VERSION ""

NS_ :

BS_:

BU_: Gateway ESR
VAL_TABLE_ ForwardReverse 1 "Reverse" 0 "Forward" ;
VAL_TABLE_ LeftRight 1 "Right Clockwise" 0 "Left CounterClockwise" ;
VAL_TABLE_ ValidInvalid 1 "Valid" 0 "Invalid" ;
VAL_TABLE_ TrueFalse 1 "True" 0 "False" ;

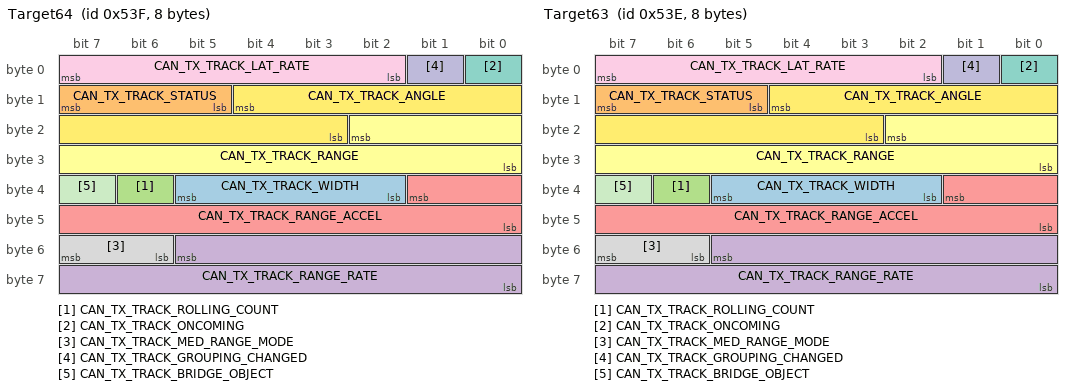
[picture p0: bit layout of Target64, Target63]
BO_ 1343 Target64: 8 Vector__XXX
 SG_ CAN_TX_TRACK_WIDTH : 37|4@0+ (0.5,0) [0|7.5] "" Vector__XXX
 SG_ CAN_TX_TRACK_STATUS : 15|3@0+ (1,0) [0|7] "" Vector__XXX
 SG_ CAN_TX_TRACK_ROLLING_COUNT : 38|1@0+ (1,0) [0|1] "" Vector__XXX
 SG_ CAN_TX_TRACK_RANGE_RATE : 53|14@0- (0.01,0) [-81.92|81.91] "m/s" Vector__XXX
 SG_ CAN_TX_TRACK_RANGE_ACCEL : 33|10@0- (0.05,0) [-25.6|25.55] "m/s^2" Vector__XXX
 SG_ CAN_TX_TRACK_RANGE : 18|11@0+ (0.1,0) [0|204.7] "m" Vector__XXX
 SG_ CAN_TX_TRACK_ONCOMING : 0|1@0+ (1,0) [0|1] "" Vector__XXX
 SG_ CAN_TX_TRACK_MED_RANGE_MODE : 55|2@0+ (1,0) [0|3] "" Vector__XXX
 SG_ CAN_TX_TRACK_LAT_RATE : 7|6@0- (0.25,0) [-8|7.75] "" Vector__XXX
 SG_ CAN_TX_TRACK_GROUPING_CHANGED : 1|1@0+ (1,0) [0|1] "" Vector__XXX
 SG_ CAN_TX_TRACK_BRIDGE_OBJECT : 39|1@0+ (1,0) [0|1] "" Vector__XXX
 SG_ CAN_TX_TRACK_ANGLE : 12|10@0- (0.1,0) [-51.2|51.1] "" Vector__XXX

BO_ 1342 Target63: 8 Vector__XXX
 SG_ CAN_TX_TRACK_WIDTH : 37|4@0+ (0.5,0) [0|7.5] "" Vector__XXX
 SG_ CAN_TX_TRACK_STATUS : 15|3@0+ (1,0) [0|7] "" Vector__XXX
 SG_ CAN_TX_TRACK_ROLLING_COUNT : 38|1@0+ (1,0) [0|1] "" Vector__XXX
 SG_ CAN_TX_TRACK_RANGE_RATE : 53|14@0- (0.01,0) [-81.92|81.91] "m/s" Vector__XXX
 SG_ CAN_TX_TRACK_RANGE_ACCEL : 33|10@0- (0.05,0) [-25.6|25.55] "m/s^2" Vector__XXX
 SG_ CAN_TX_TRACK_RANGE : 18|11@0+ (0.1,0) [0|204.7] "m" Vector__XXX
 SG_ CAN_TX_TRACK_ONCOMING : 0|1@0+ (1,0) [0|1] "" Vector__XXX
 SG_ CAN_TX_TRACK_MED_RANGE_MODE : 55|2@0+ (1,0) [0|3] "" Vector__XXX
 SG_ CAN_TX_TRACK_LAT_RATE : 7|6@0- (0.25,0) [-8|7.75] "" Vector__XXX
 SG_ CAN_TX_TRACK_GROUPING_CHANGED : 1|1@0+ (1,0) [0|1] "" Vector__XXX
 SG_ CAN_TX_TRACK_BRIDGE_OBJECT : 39|1@0+ (1,0) [0|1] "" Vector__XXX
 SG_ CAN_TX_TRACK_ANGLE : 12|10@0- (0.1,0) [-51.2|51.1] "" Vector__XXX

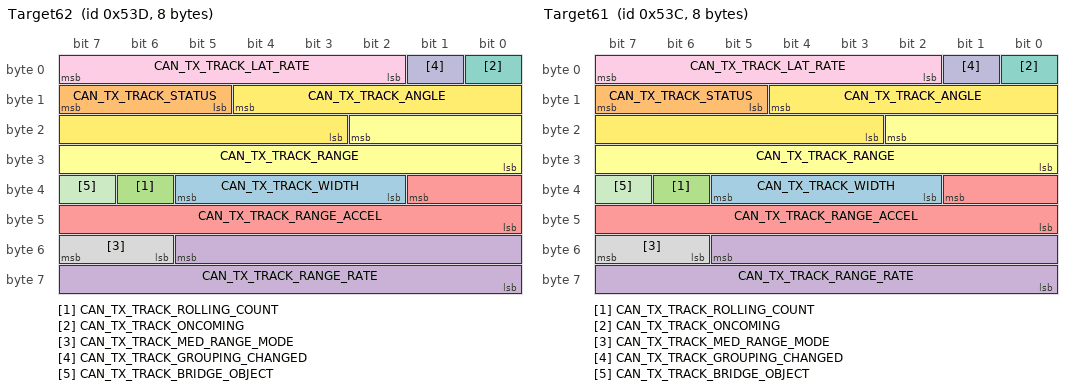
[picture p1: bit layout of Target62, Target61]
BO_ 1341 Target62: 8 Vector__XXX
 SG_ CAN_TX_TRACK_WIDTH : 37|4@0+ (0.5,0) [0|7.5] "" Vector__XXX
 SG_ CAN_TX_TRACK_STATUS : 15|3@0+ (1,0) [0|7] "" Vector__XXX
 SG_ CAN_TX_TRACK_ROLLING_COUNT : 38|1@0+ (1,0) [0|1] "" Vector__XXX
 SG_ CAN_TX_TRACK_RANGE_RATE : 53|14@0- (0.01,0) [-81.92|81.91] "m/s" Vector__XXX
 SG_ CAN_TX_TRACK_RANGE_ACCEL : 33|10@0- (0.05,0) [-25.6|25.55] "m/s^2" Vector__XXX
 SG_ CAN_TX_TRACK_RANGE : 18|11@0+ (0.1,0) [0|204.7] "m" Vector__XXX
 SG_ CAN_TX_TRACK_ONCOMING : 0|1@0+ (1,0) [0|1] "" Vector__XXX
 SG_ CAN_TX_TRACK_MED_RANGE_MODE : 55|2@0+ (1,0) [0|3] "" Vector__XXX
 SG_ CAN_TX_TRACK_LAT_RATE : 7|6@0- (0.25,0) [-8|7.75] "" Vector__XXX
 SG_ CAN_TX_TRACK_GROUPING_CHANGED : 1|1@0+ (1,0) [0|1] "" Vector__XXX
 SG_ CAN_TX_TRACK_BRIDGE_OBJECT : 39|1@0+ (1,0) [0|1] "" Vector__XXX
 SG_ CAN_TX_TRACK_ANGLE : 12|10@0- (0.1,0) [-51.2|51.1] "" Vector__XXX

BO_ 1340 Target61: 8 Vector__XXX
 SG_ CAN_TX_TRACK_WIDTH : 37|4@0+ (0.5,0) [0|7.5] "" Vector__XXX
 SG_ CAN_TX_TRACK_STATUS : 15|3@0+ (1,0) [0|7] "" Vector__XXX
 SG_ CAN_TX_TRACK_ROLLING_COUNT : 38|1@0+ (1,0) [0|1] "" Vector__XXX
 SG_ CAN_TX_TRACK_RANGE_RATE : 53|14@0- (0.01,0) [-81.92|81.91] "m/s" Vector__XXX
 SG_ CAN_TX_TRACK_RANGE_ACCEL : 33|10@0- (0.05,0) [-25.6|25.55] "m/s^2" Vector__XXX
 SG_ CAN_TX_TRACK_RANGE : 18|11@0+ (0.1,0) [0|204.7] "m" Vector__XXX
 SG_ CAN_TX_TRACK_ONCOMING : 0|1@0+ (1,0) [0|1] "" Vector__XXX
 SG_ CAN_TX_TRACK_MED_RANGE_MODE : 55|2@0+ (1,0) [0|3] "" Vector__XXX
 SG_ CAN_TX_TRACK_LAT_RATE : 7|6@0- (0.25,0) [-8|7.75] "" Vector__XXX
 SG_ CAN_TX_TRACK_GROUPING_CHANGED : 1|1@0+ (1,0) [0|1] "" Vector__XXX
 SG_ CAN_TX_TRACK_BRIDGE_OBJECT : 39|1@0+ (1,0) [0|1] "" Vector__XXX
 SG_ CAN_TX_TRACK_ANGLE : 12|10@0- (0.1,0) [-51.2|51.1] "" Vector__XXX

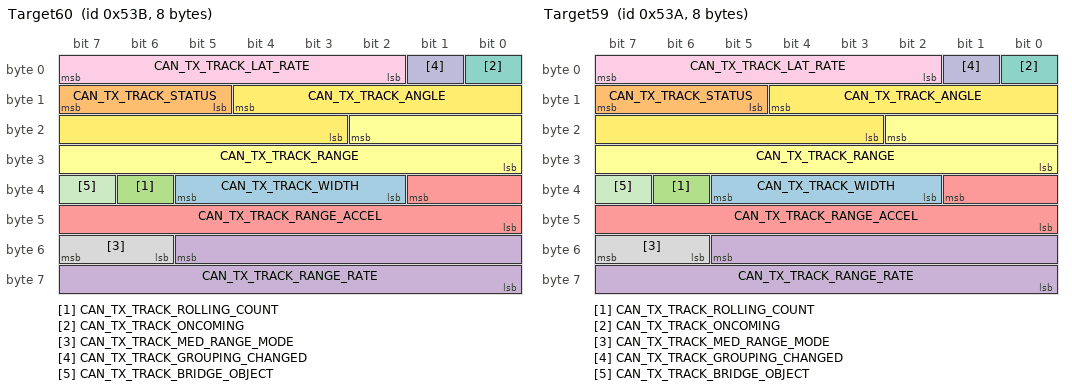
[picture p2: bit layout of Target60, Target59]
BO_ 1339 Target60: 8 Vector__XXX
 SG_ CAN_TX_TRACK_WIDTH : 37|4@0+ (0.5,0) [0|7.5] "" Vector__XXX
 SG_ CAN_TX_TRACK_STATUS : 15|3@0+ (1,0) [0|7] "" Vector__XXX
 SG_ CAN_TX_TRACK_ROLLING_COUNT : 38|1@0+ (1,0) [0|1] "" Vector__XXX
 SG_ CAN_TX_TRACK_RANGE_RATE : 53|14@0- (0.01,0) [-81.92|81.91] "m/s" Vector__XXX
 SG_ CAN_TX_TRACK_RANGE_ACCEL : 33|10@0- (0.05,0) [-25.6|25.55] "m/s^2" Vector__XXX
 SG_ CAN_TX_TRACK_RANGE : 18|11@0+ (0.1,0) [0|204.7] "m" Vector__XXX
 SG_ CAN_TX_TRACK_ONCOMING : 0|1@0+ (1,0) [0|1] "" Vector__XXX
 SG_ CAN_TX_TRACK_MED_RANGE_MODE : 55|2@0+ (1,0) [0|3] "" Vector__XXX
 SG_ CAN_TX_TRACK_LAT_RATE : 7|6@0- (0.25,0) [-8|7.75] "" Vector__XXX
 SG_ CAN_TX_TRACK_GROUPING_CHANGED : 1|1@0+ (1,0) [0|1] "" Vector__XXX
 SG_ CAN_TX_TRACK_BRIDGE_OBJECT : 39|1@0+ (1,0) [0|1] "" Vector__XXX
 SG_ CAN_TX_TRACK_ANGLE : 12|10@0- (0.1,0) [-51.2|51.1] "" Vector__XXX

BO_ 1338 Target59: 8 Vector__XXX
 SG_ CAN_TX_TRACK_WIDTH : 37|4@0+ (0.5,0) [0|7.5] "" Vector__XXX
 SG_ CAN_TX_TRACK_STATUS : 15|3@0+ (1,0) [0|7] "" Vector__XXX
 SG_ CAN_TX_TRACK_ROLLING_COUNT : 38|1@0+ (1,0) [0|1] "" Vector__XXX
 SG_ CAN_TX_TRACK_RANGE_RATE : 53|14@0- (0.01,0) [-81.92|81.91] "m/s" Vector__XXX
 SG_ CAN_TX_TRACK_RANGE_ACCEL : 33|10@0- (0.05,0) [-25.6|25.55] "m/s^2" Vector__XXX
 SG_ CAN_TX_TRACK_RANGE : 18|11@0+ (0.1,0) [0|204.7] "m" Vector__XXX
 SG_ CAN_TX_TRACK_ONCOMING : 0|1@0+ (1,0) [0|1] "" Vector__XXX
 SG_ CAN_TX_TRACK_MED_RANGE_MODE : 55|2@0+ (1,0) [0|3] "" Vector__XXX
 SG_ CAN_TX_TRACK_LAT_RATE : 7|6@0- (0.25,0) [-8|7.75] "" Vector__XXX
 SG_ CAN_TX_TRACK_GROUPING_CHANGED : 1|1@0+ (1,0) [0|1] "" Vector__XXX
 SG_ CAN_TX_TRACK_BRIDGE_OBJECT : 39|1@0+ (1,0) [0|1] "" Vector__XXX
 SG_ CAN_TX_TRACK_ANGLE : 12|10@0- (0.1,0) [-51.2|51.1] "" Vector__XXX

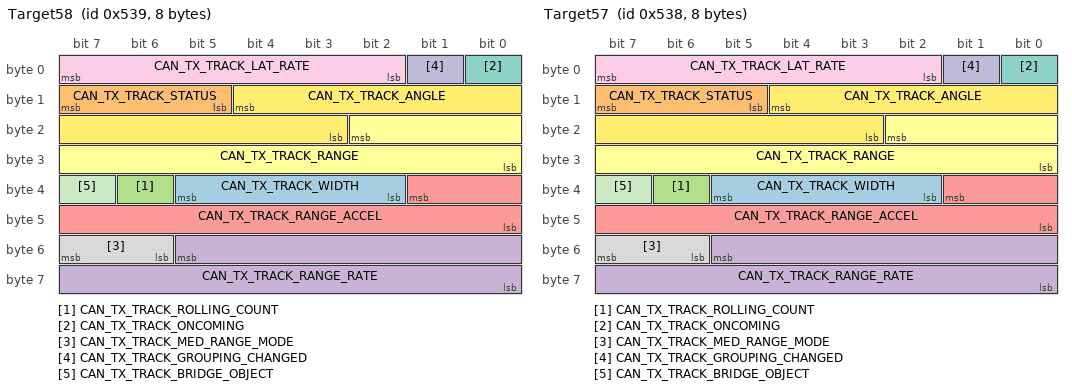
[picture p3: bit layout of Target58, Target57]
BO_ 1337 Target58: 8 Vector__XXX
 SG_ CAN_TX_TRACK_WIDTH : 37|4@0+ (0.5,0) [0|7.5] "" Vector__XXX
 SG_ CAN_TX_TRACK_STATUS : 15|3@0+ (1,0) [0|7] "" Vector__XXX
 SG_ CAN_TX_TRACK_ROLLING_COUNT : 38|1@0+ (1,0) [0|1] "" Vector__XXX
 SG_ CAN_TX_TRACK_RANGE_RATE : 53|14@0- (0.01,0) [-81.92|81.91] "m/s" Vector__XXX
 SG_ CAN_TX_TRACK_RANGE_ACCEL : 33|10@0- (0.05,0) [-25.6|25.55] "m/s^2" Vector__XXX
 SG_ CAN_TX_TRACK_RANGE : 18|11@0+ (0.1,0) [0|204.7] "m" Vector__XXX
 SG_ CAN_TX_TRACK_ONCOMING : 0|1@0+ (1,0) [0|1] "" Vector__XXX
 SG_ CAN_TX_TRACK_MED_RANGE_MODE : 55|2@0+ (1,0) [0|3] "" Vector__XXX
 SG_ CAN_TX_TRACK_LAT_RATE : 7|6@0- (0.25,0) [-8|7.75] "" Vector__XXX
 SG_ CAN_TX_TRACK_GROUPING_CHANGED : 1|1@0+ (1,0) [0|1] "" Vector__XXX
 SG_ CAN_TX_TRACK_BRIDGE_OBJECT : 39|1@0+ (1,0) [0|1] "" Vector__XXX
 SG_ CAN_TX_TRACK_ANGLE : 12|10@0- (0.1,0) [-51.2|51.1] "" Vector__XXX

BO_ 1336 Target57: 8 Vector__XXX
 SG_ CAN_TX_TRACK_WIDTH : 37|4@0+ (0.5,0) [0|7.5] "" Vector__XXX
 SG_ CAN_TX_TRACK_STATUS : 15|3@0+ (1,0) [0|7] "" Vector__XXX
 SG_ CAN_TX_TRACK_ROLLING_COUNT : 38|1@0+ (1,0) [0|1] "" Vector__XXX
 SG_ CAN_TX_TRACK_RANGE_RATE : 53|14@0- (0.01,0) [-81.92|81.91] "m/s" Vector__XXX
 SG_ CAN_TX_TRACK_RANGE_ACCEL : 33|10@0- (0.05,0) [-25.6|25.55] "m/s^2" Vector__XXX
 SG_ CAN_TX_TRACK_RANGE : 18|11@0+ (0.1,0) [0|204.7] "m" Vector__XXX
 SG_ CAN_TX_TRACK_ONCOMING : 0|1@0+ (1,0) [0|1] "" Vector__XXX
 SG_ CAN_TX_TRACK_MED_RANGE_MODE : 55|2@0+ (1,0) [0|3] "" Vector__XXX
 SG_ CAN_TX_TRACK_LAT_RATE : 7|6@0- (0.25,0) [-8|7.75] "" Vector__XXX
 SG_ CAN_TX_TRACK_GROUPING_CHANGED : 1|1@0+ (1,0) [0|1] "" Vector__XXX
 SG_ CAN_TX_TRACK_BRIDGE_OBJECT : 39|1@0+ (1,0) [0|1] "" Vector__XXX
 SG_ CAN_TX_TRACK_ANGLE : 12|10@0- (0.1,0) [-51.2|51.1] "" Vector__XXX

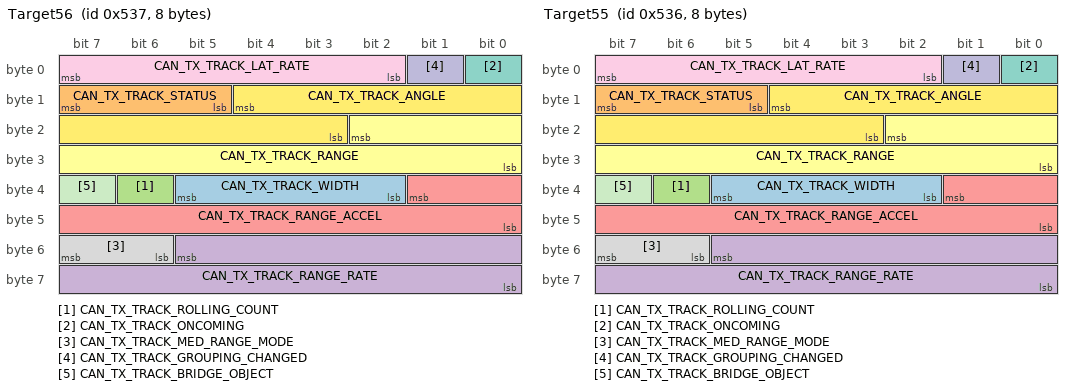
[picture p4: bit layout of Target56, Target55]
BO_ 1335 Target56: 8 Vector__XXX
 SG_ CAN_TX_TRACK_WIDTH : 37|4@0+ (0.5,0) [0|7.5] "" Vector__XXX
 SG_ CAN_TX_TRACK_STATUS : 15|3@0+ (1,0) [0|7] "" Vector__XXX
 SG_ CAN_TX_TRACK_ROLLING_COUNT : 38|1@0+ (1,0) [0|1] "" Vector__XXX
 SG_ CAN_TX_TRACK_RANGE_RATE : 53|14@0- (0.01,0) [-81.92|81.91] "m/s" Vector__XXX
 SG_ CAN_TX_TRACK_RANGE_ACCEL : 33|10@0- (0.05,0) [-25.6|25.55] "m/s^2" Vector__XXX
 SG_ CAN_TX_TRACK_RANGE : 18|11@0+ (0.1,0) [0|204.7] "m" Vector__XXX
 SG_ CAN_TX_TRACK_ONCOMING : 0|1@0+ (1,0) [0|1] "" Vector__XXX
 SG_ CAN_TX_TRACK_MED_RANGE_MODE : 55|2@0+ (1,0) [0|3] "" Vector__XXX
 SG_ CAN_TX_TRACK_LAT_RATE : 7|6@0- (0.25,0) [-8|7.75] "" Vector__XXX
 SG_ CAN_TX_TRACK_GROUPING_CHANGED : 1|1@0+ (1,0) [0|1] "" Vector__XXX
 SG_ CAN_TX_TRACK_BRIDGE_OBJECT : 39|1@0+ (1,0) [0|1] "" Vector__XXX
 SG_ CAN_TX_TRACK_ANGLE : 12|10@0- (0.1,0) [-51.2|51.1] "" Vector__XXX

BO_ 1334 Target55: 8 Vector__XXX
 SG_ CAN_TX_TRACK_WIDTH : 37|4@0+ (0.5,0) [0|7.5] "" Vector__XXX
 SG_ CAN_TX_TRACK_STATUS : 15|3@0+ (1,0) [0|7] "" Vector__XXX
 SG_ CAN_TX_TRACK_ROLLING_COUNT : 38|1@0+ (1,0) [0|1] "" Vector__XXX
 SG_ CAN_TX_TRACK_RANGE_RATE : 53|14@0- (0.01,0) [-81.92|81.91] "m/s" Vector__XXX
 SG_ CAN_TX_TRACK_RANGE_ACCEL : 33|10@0- (0.05,0) [-25.6|25.55] "m/s^2" Vector__XXX
 SG_ CAN_TX_TRACK_RANGE : 18|11@0+ (0.1,0) [0|204.7] "m" Vector__XXX
 SG_ CAN_TX_TRACK_ONCOMING : 0|1@0+ (1,0) [0|1] "" Vector__XXX
 SG_ CAN_TX_TRACK_MED_RANGE_MODE : 55|2@0+ (1,0) [0|3] "" Vector__XXX
 SG_ CAN_TX_TRACK_LAT_RATE : 7|6@0- (0.25,0) [-8|7.75] "" Vector__XXX
 SG_ CAN_TX_TRACK_GROUPING_CHANGED : 1|1@0+ (1,0) [0|1] "" Vector__XXX
 SG_ CAN_TX_TRACK_BRIDGE_OBJECT : 39|1@0+ (1,0) [0|1] "" Vector__XXX
 SG_ CAN_TX_TRACK_ANGLE : 12|10@0- (0.1,0) [-51.2|51.1] "" Vector__XXX

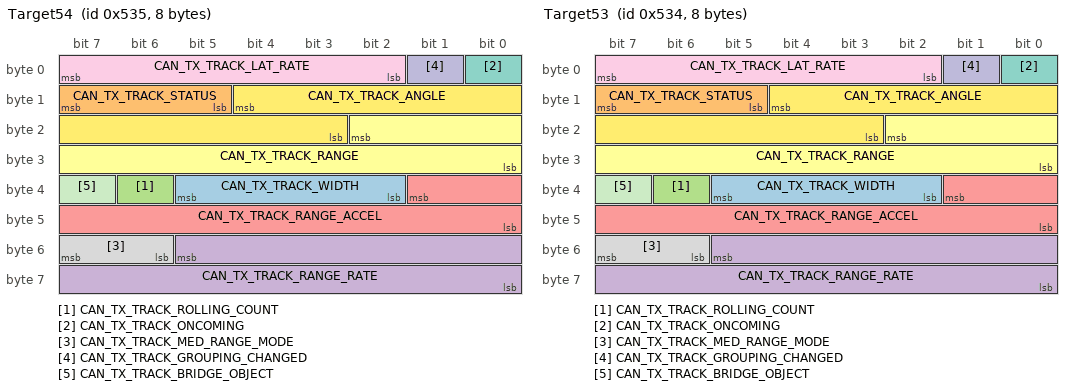
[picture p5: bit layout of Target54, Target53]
BO_ 1333 Target54: 8 Vector__XXX
 SG_ CAN_TX_TRACK_WIDTH : 37|4@0+ (0.5,0) [0|7.5] "" Vector__XXX
 SG_ CAN_TX_TRACK_STATUS : 15|3@0+ (1,0) [0|7] "" Vector__XXX
 SG_ CAN_TX_TRACK_ROLLING_COUNT : 38|1@0+ (1,0) [0|1] "" Vector__XXX
 SG_ CAN_TX_TRACK_RANGE_RATE : 53|14@0- (0.01,0) [-81.92|81.91] "m/s" Vector__XXX
 SG_ CAN_TX_TRACK_RANGE_ACCEL : 33|10@0- (0.05,0) [-25.6|25.55] "m/s^2" Vector__XXX
 SG_ CAN_TX_TRACK_RANGE : 18|11@0+ (0.1,0) [0|204.7] "m" Vector__XXX
 SG_ CAN_TX_TRACK_ONCOMING : 0|1@0+ (1,0) [0|1] "" Vector__XXX
 SG_ CAN_TX_TRACK_MED_RANGE_MODE : 55|2@0+ (1,0) [0|3] "" Vector__XXX
 SG_ CAN_TX_TRACK_LAT_RATE : 7|6@0- (0.25,0) [-8|7.75] "" Vector__XXX
 SG_ CAN_TX_TRACK_GROUPING_CHANGED : 1|1@0+ (1,0) [0|1] "" Vector__XXX
 SG_ CAN_TX_TRACK_BRIDGE_OBJECT : 39|1@0+ (1,0) [0|1] "" Vector__XXX
 SG_ CAN_TX_TRACK_ANGLE : 12|10@0- (0.1,0) [-51.2|51.1] "" Vector__XXX

BO_ 1332 Target53: 8 Vector__XXX
 SG_ CAN_TX_TRACK_WIDTH : 37|4@0+ (0.5,0) [0|7.5] "" Vector__XXX
 SG_ CAN_TX_TRACK_STATUS : 15|3@0+ (1,0) [0|7] "" Vector__XXX
 SG_ CAN_TX_TRACK_ROLLING_COUNT : 38|1@0+ (1,0) [0|1] "" Vector__XXX
 SG_ CAN_TX_TRACK_RANGE_RATE : 53|14@0- (0.01,0) [-81.92|81.91] "m/s" Vector__XXX
 SG_ CAN_TX_TRACK_RANGE_ACCEL : 33|10@0- (0.05,0) [-25.6|25.55] "m/s^2" Vector__XXX
 SG_ CAN_TX_TRACK_RANGE : 18|11@0+ (0.1,0) [0|204.7] "m" Vector__XXX
 SG_ CAN_TX_TRACK_ONCOMING : 0|1@0+ (1,0) [0|1] "" Vector__XXX
 SG_ CAN_TX_TRACK_MED_RANGE_MODE : 55|2@0+ (1,0) [0|3] "" Vector__XXX
 SG_ CAN_TX_TRACK_LAT_RATE : 7|6@0- (0.25,0) [-8|7.75] "" Vector__XXX
 SG_ CAN_TX_TRACK_GROUPING_CHANGED : 1|1@0+ (1,0) [0|1] "" Vector__XXX
 SG_ CAN_TX_TRACK_BRIDGE_OBJECT : 39|1@0+ (1,0) [0|1] "" Vector__XXX
 SG_ CAN_TX_TRACK_ANGLE : 12|10@0- (0.1,0) [-51.2|51.1] "" Vector__XXX

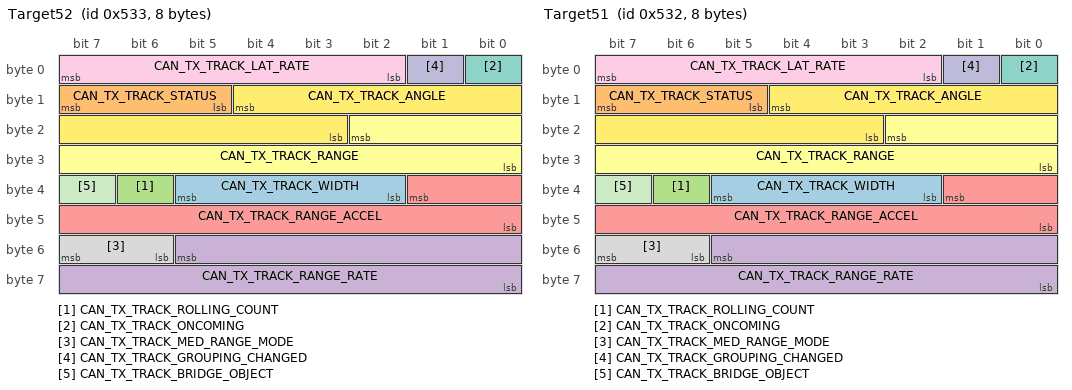
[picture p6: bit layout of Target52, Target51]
BO_ 1331 Target52: 8 Vector__XXX
 SG_ CAN_TX_TRACK_WIDTH : 37|4@0+ (0.5,0) [0|7.5] "" Vector__XXX
 SG_ CAN_TX_TRACK_STATUS : 15|3@0+ (1,0) [0|7] "" Vector__XXX
 SG_ CAN_TX_TRACK_ROLLING_COUNT : 38|1@0+ (1,0) [0|1] "" Vector__XXX
 SG_ CAN_TX_TRACK_RANGE_RATE : 53|14@0- (0.01,0) [-81.92|81.91] "m/s" Vector__XXX
 SG_ CAN_TX_TRACK_RANGE_ACCEL : 33|10@0- (0.05,0) [-25.6|25.55] "m/s^2" Vector__XXX
 SG_ CAN_TX_TRACK_RANGE : 18|11@0+ (0.1,0) [0|204.7] "m" Vector__XXX
 SG_ CAN_TX_TRACK_ONCOMING : 0|1@0+ (1,0) [0|1] "" Vector__XXX
 SG_ CAN_TX_TRACK_MED_RANGE_MODE : 55|2@0+ (1,0) [0|3] "" Vector__XXX
 SG_ CAN_TX_TRACK_LAT_RATE : 7|6@0- (0.25,0) [-8|7.75] "" Vector__XXX
 SG_ CAN_TX_TRACK_GROUPING_CHANGED : 1|1@0+ (1,0) [0|1] "" Vector__XXX
 SG_ CAN_TX_TRACK_BRIDGE_OBJECT : 39|1@0+ (1,0) [0|1] "" Vector__XXX
 SG_ CAN_TX_TRACK_ANGLE : 12|10@0- (0.1,0) [-51.2|51.1] "" Vector__XXX

BO_ 1330 Target51: 8 Vector__XXX
 SG_ CAN_TX_TRACK_WIDTH : 37|4@0+ (0.5,0) [0|7.5] "" Vector__XXX
 SG_ CAN_TX_TRACK_STATUS : 15|3@0+ (1,0) [0|7] "" Vector__XXX
 SG_ CAN_TX_TRACK_ROLLING_COUNT : 38|1@0+ (1,0) [0|1] "" Vector__XXX
 SG_ CAN_TX_TRACK_RANGE_RATE : 53|14@0- (0.01,0) [-81.92|81.91] "m/s" Vector__XXX
 SG_ CAN_TX_TRACK_RANGE_ACCEL : 33|10@0- (0.05,0) [-25.6|25.55] "m/s^2" Vector__XXX
 SG_ CAN_TX_TRACK_RANGE : 18|11@0+ (0.1,0) [0|204.7] "m" Vector__XXX
 SG_ CAN_TX_TRACK_ONCOMING : 0|1@0+ (1,0) [0|1] "" Vector__XXX
 SG_ CAN_TX_TRACK_MED_RANGE_MODE : 55|2@0+ (1,0) [0|3] "" Vector__XXX
 SG_ CAN_TX_TRACK_LAT_RATE : 7|6@0- (0.25,0) [-8|7.75] "" Vector__XXX
 SG_ CAN_TX_TRACK_GROUPING_CHANGED : 1|1@0+ (1,0) [0|1] "" Vector__XXX
 SG_ CAN_TX_TRACK_BRIDGE_OBJECT : 39|1@0+ (1,0) [0|1] "" Vector__XXX
 SG_ CAN_TX_TRACK_ANGLE : 12|10@0- (0.1,0) [-51.2|51.1] "" Vector__XXX

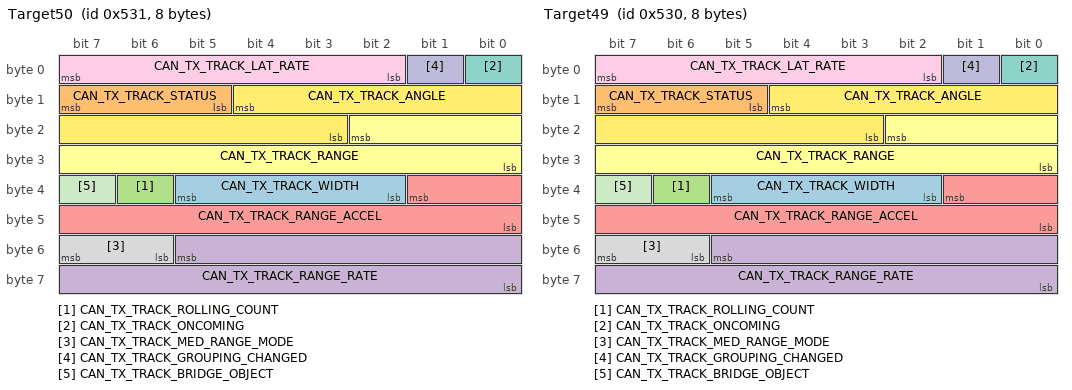
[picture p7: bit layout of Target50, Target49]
BO_ 1329 Target50: 8 Vector__XXX
 SG_ CAN_TX_TRACK_WIDTH : 37|4@0+ (0.5,0) [0|7.5] "" Vector__XXX
 SG_ CAN_TX_TRACK_STATUS : 15|3@0+ (1,0) [0|7] "" Vector__XXX
 SG_ CAN_TX_TRACK_ROLLING_COUNT : 38|1@0+ (1,0) [0|1] "" Vector__XXX
 SG_ CAN_TX_TRACK_RANGE_RATE : 53|14@0- (0.01,0) [-81.92|81.91] "m/s" Vector__XXX
 SG_ CAN_TX_TRACK_RANGE_ACCEL : 33|10@0- (0.05,0) [-25.6|25.55] "m/s^2" Vector__XXX
 SG_ CAN_TX_TRACK_RANGE : 18|11@0+ (0.1,0) [0|204.7] "m" Vector__XXX
 SG_ CAN_TX_TRACK_ONCOMING : 0|1@0+ (1,0) [0|1] "" Vector__XXX
 SG_ CAN_TX_TRACK_MED_RANGE_MODE : 55|2@0+ (1,0) [0|3] "" Vector__XXX
 SG_ CAN_TX_TRACK_LAT_RATE : 7|6@0- (0.25,0) [-8|7.75] "" Vector__XXX
 SG_ CAN_TX_TRACK_GROUPING_CHANGED : 1|1@0+ (1,0) [0|1] "" Vector__XXX
 SG_ CAN_TX_TRACK_BRIDGE_OBJECT : 39|1@0+ (1,0) [0|1] "" Vector__XXX
 SG_ CAN_TX_TRACK_ANGLE : 12|10@0- (0.1,0) [-51.2|51.1] "" Vector__XXX

BO_ 1328 Target49: 8 Vector__XXX
 SG_ CAN_TX_TRACK_WIDTH : 37|4@0+ (0.5,0) [0|7.5] "" Vector__XXX
 SG_ CAN_TX_TRACK_STATUS : 15|3@0+ (1,0) [0|7] "" Vector__XXX
 SG_ CAN_TX_TRACK_ROLLING_COUNT : 38|1@0+ (1,0) [0|1] "" Vector__XXX
 SG_ CAN_TX_TRACK_RANGE_RATE : 53|14@0- (0.01,0) [-81.92|81.91] "m/s" Vector__XXX
 SG_ CAN_TX_TRACK_RANGE_ACCEL : 33|10@0- (0.05,0) [-25.6|25.55] "m/s^2" Vector__XXX
 SG_ CAN_TX_TRACK_RANGE : 18|11@0+ (0.1,0) [0|204.7] "m" Vector__XXX
 SG_ CAN_TX_TRACK_ONCOMING : 0|1@0+ (1,0) [0|1] "" Vector__XXX
 SG_ CAN_TX_TRACK_MED_RANGE_MODE : 55|2@0+ (1,0) [0|3] "" Vector__XXX
 SG_ CAN_TX_TRACK_LAT_RATE : 7|6@0- (0.25,0) [-8|7.75] "" Vector__XXX
 SG_ CAN_TX_TRACK_GROUPING_CHANGED : 1|1@0+ (1,0) [0|1] "" Vector__XXX
 SG_ CAN_TX_TRACK_BRIDGE_OBJECT : 39|1@0+ (1,0) [0|1] "" Vector__XXX
 SG_ CAN_TX_TRACK_ANGLE : 12|10@0- (0.1,0) [-51.2|51.1] "" Vector__XXX

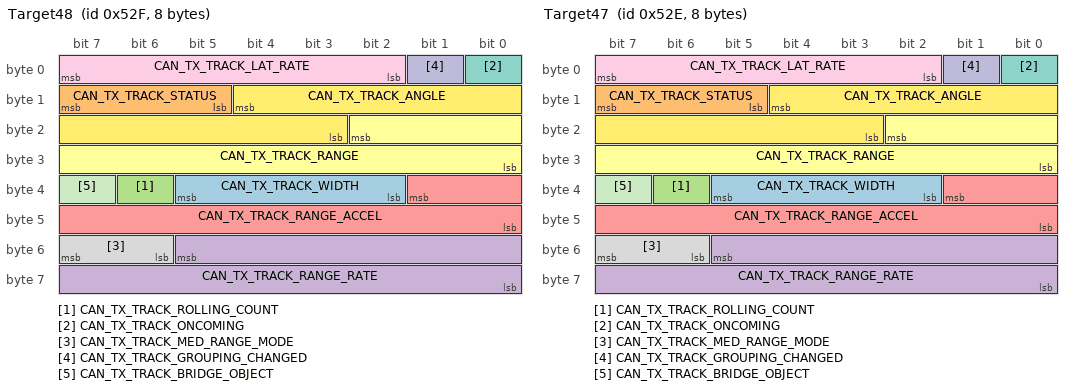
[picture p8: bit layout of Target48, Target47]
BO_ 1327 Target48: 8 Vector__XXX
 SG_ CAN_TX_TRACK_WIDTH : 37|4@0+ (0.5,0) [0|7.5] "" Vector__XXX
 SG_ CAN_TX_TRACK_STATUS : 15|3@0+ (1,0) [0|7] "" Vector__XXX
 SG_ CAN_TX_TRACK_ROLLING_COUNT : 38|1@0+ (1,0) [0|1] "" Vector__XXX
 SG_ CAN_TX_TRACK_RANGE_RATE : 53|14@0- (0.01,0) [-81.92|81.91] "m/s" Vector__XXX
 SG_ CAN_TX_TRACK_RANGE_ACCEL : 33|10@0- (0.05,0) [-25.6|25.55] "m/s^2" Vector__XXX
 SG_ CAN_TX_TRACK_RANGE : 18|11@0+ (0.1,0) [0|204.7] "m" Vector__XXX
 SG_ CAN_TX_TRACK_ONCOMING : 0|1@0+ (1,0) [0|1] "" Vector__XXX
 SG_ CAN_TX_TRACK_MED_RANGE_MODE : 55|2@0+ (1,0) [0|3] "" Vector__XXX
 SG_ CAN_TX_TRACK_LAT_RATE : 7|6@0- (0.25,0) [-8|7.75] "" Vector__XXX
 SG_ CAN_TX_TRACK_GROUPING_CHANGED : 1|1@0+ (1,0) [0|1] "" Vector__XXX
 SG_ CAN_TX_TRACK_BRIDGE_OBJECT : 39|1@0+ (1,0) [0|1] "" Vector__XXX
 SG_ CAN_TX_TRACK_ANGLE : 12|10@0- (0.1,0) [-51.2|51.1] "" Vector__XXX

BO_ 1326 Target47: 8 Vector__XXX
 SG_ CAN_TX_TRACK_WIDTH : 37|4@0+ (0.5,0) [0|7.5] "" Vector__XXX
 SG_ CAN_TX_TRACK_STATUS : 15|3@0+ (1,0) [0|7] "" Vector__XXX
 SG_ CAN_TX_TRACK_ROLLING_COUNT : 38|1@0+ (1,0) [0|1] "" Vector__XXX
 SG_ CAN_TX_TRACK_RANGE_RATE : 53|14@0- (0.01,0) [-81.92|81.91] "m/s" Vector__XXX
 SG_ CAN_TX_TRACK_RANGE_ACCEL : 33|10@0- (0.05,0) [-25.6|25.55] "m/s^2" Vector__XXX
 SG_ CAN_TX_TRACK_RANGE : 18|11@0+ (0.1,0) [0|204.7] "m" Vector__XXX
 SG_ CAN_TX_TRACK_ONCOMING : 0|1@0+ (1,0) [0|1] "" Vector__XXX
 SG_ CAN_TX_TRACK_MED_RANGE_MODE : 55|2@0+ (1,0) [0|3] "" Vector__XXX
 SG_ CAN_TX_TRACK_LAT_RATE : 7|6@0- (0.25,0) [-8|7.75] "" Vector__XXX
 SG_ CAN_TX_TRACK_GROUPING_CHANGED : 1|1@0+ (1,0) [0|1] "" Vector__XXX
 SG_ CAN_TX_TRACK_BRIDGE_OBJECT : 39|1@0+ (1,0) [0|1] "" Vector__XXX
 SG_ CAN_TX_TRACK_ANGLE : 12|10@0- (0.1,0) [-51.2|51.1] "" Vector__XXX

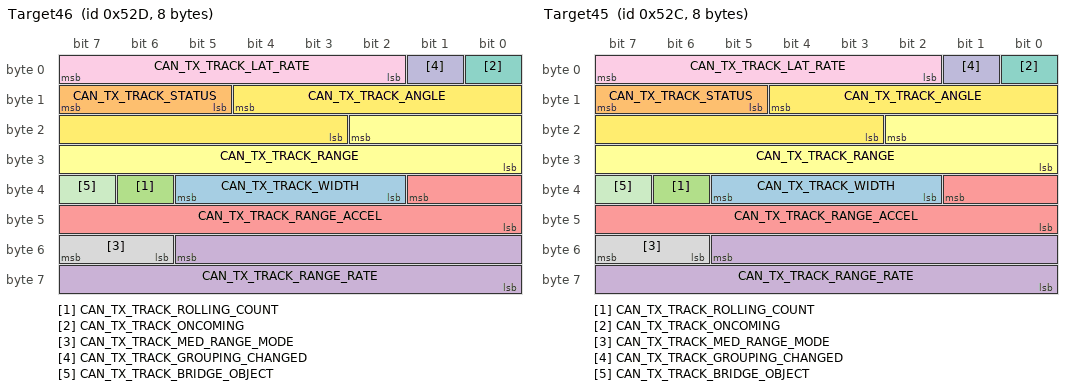
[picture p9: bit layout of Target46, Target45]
BO_ 1325 Target46: 8 Vector__XXX
 SG_ CAN_TX_TRACK_WIDTH : 37|4@0+ (0.5,0) [0|7.5] "" Vector__XXX
 SG_ CAN_TX_TRACK_STATUS : 15|3@0+ (1,0) [0|7] "" Vector__XXX
 SG_ CAN_TX_TRACK_ROLLING_COUNT : 38|1@0+ (1,0) [0|1] "" Vector__XXX
 SG_ CAN_TX_TRACK_RANGE_RATE : 53|14@0- (0.01,0) [-81.92|81.91] "m/s" Vector__XXX
 SG_ CAN_TX_TRACK_RANGE_ACCEL : 33|10@0- (0.05,0) [-25.6|25.55] "m/s^2" Vector__XXX
 SG_ CAN_TX_TRACK_RANGE : 18|11@0+ (0.1,0) [0|204.7] "m" Vector__XXX
 SG_ CAN_TX_TRACK_ONCOMING : 0|1@0+ (1,0) [0|1] "" Vector__XXX
 SG_ CAN_TX_TRACK_MED_RANGE_MODE : 55|2@0+ (1,0) [0|3] "" Vector__XXX
 SG_ CAN_TX_TRACK_LAT_RATE : 7|6@0- (0.25,0) [-8|7.75] "" Vector__XXX
 SG_ CAN_TX_TRACK_GROUPING_CHANGED : 1|1@0+ (1,0) [0|1] "" Vector__XXX
 SG_ CAN_TX_TRACK_BRIDGE_OBJECT : 39|1@0+ (1,0) [0|1] "" Vector__XXX
 SG_ CAN_TX_TRACK_ANGLE : 12|10@0- (0.1,0) [-51.2|51.1] "" Vector__XXX

BO_ 1324 Target45: 8 Vector__XXX
 SG_ CAN_TX_TRACK_WIDTH : 37|4@0+ (0.5,0) [0|7.5] "" Vector__XXX
 SG_ CAN_TX_TRACK_STATUS : 15|3@0+ (1,0) [0|7] "" Vector__XXX
 SG_ CAN_TX_TRACK_ROLLING_COUNT : 38|1@0+ (1,0) [0|1] "" Vector__XXX
 SG_ CAN_TX_TRACK_RANGE_RATE : 53|14@0- (0.01,0) [-81.92|81.91] "m/s" Vector__XXX
 SG_ CAN_TX_TRACK_RANGE_ACCEL : 33|10@0- (0.05,0) [-25.6|25.55] "m/s^2" Vector__XXX
 SG_ CAN_TX_TRACK_RANGE : 18|11@0+ (0.1,0) [0|204.7] "m" Vector__XXX
 SG_ CAN_TX_TRACK_ONCOMING : 0|1@0+ (1,0) [0|1] "" Vector__XXX
 SG_ CAN_TX_TRACK_MED_RANGE_MODE : 55|2@0+ (1,0) [0|3] "" Vector__XXX
 SG_ CAN_TX_TRACK_LAT_RATE : 7|6@0- (0.25,0) [-8|7.75] "" Vector__XXX
 SG_ CAN_TX_TRACK_GROUPING_CHANGED : 1|1@0+ (1,0) [0|1] "" Vector__XXX
 SG_ CAN_TX_TRACK_BRIDGE_OBJECT : 39|1@0+ (1,0) [0|1] "" Vector__XXX
 SG_ CAN_TX_TRACK_ANGLE : 12|10@0- (0.1,0) [-51.2|51.1] "" Vector__XXX

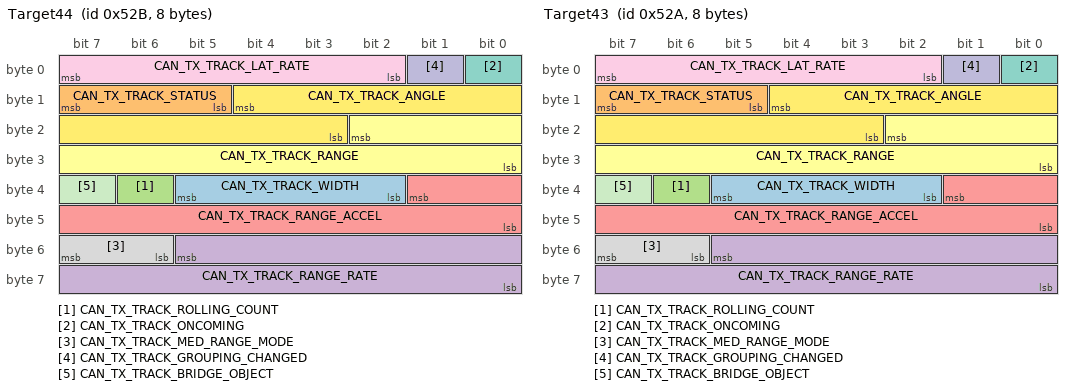
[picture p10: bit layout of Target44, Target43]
BO_ 1323 Target44: 8 Vector__XXX
 SG_ CAN_TX_TRACK_WIDTH : 37|4@0+ (0.5,0) [0|7.5] "" Vector__XXX
 SG_ CAN_TX_TRACK_STATUS : 15|3@0+ (1,0) [0|7] "" Vector__XXX
 SG_ CAN_TX_TRACK_ROLLING_COUNT : 38|1@0+ (1,0) [0|1] "" Vector__XXX
 SG_ CAN_TX_TRACK_RANGE_RATE : 53|14@0- (0.01,0) [-81.92|81.91] "m/s" Vector__XXX
 SG_ CAN_TX_TRACK_RANGE_ACCEL : 33|10@0- (0.05,0) [-25.6|25.55] "m/s^2" Vector__XXX
 SG_ CAN_TX_TRACK_RANGE : 18|11@0+ (0.1,0) [0|204.7] "m" Vector__XXX
 SG_ CAN_TX_TRACK_ONCOMING : 0|1@0+ (1,0) [0|1] "" Vector__XXX
 SG_ CAN_TX_TRACK_MED_RANGE_MODE : 55|2@0+ (1,0) [0|3] "" Vector__XXX
 SG_ CAN_TX_TRACK_LAT_RATE : 7|6@0- (0.25,0) [-8|7.75] "" Vector__XXX
 SG_ CAN_TX_TRACK_GROUPING_CHANGED : 1|1@0+ (1,0) [0|1] "" Vector__XXX
 SG_ CAN_TX_TRACK_BRIDGE_OBJECT : 39|1@0+ (1,0) [0|1] "" Vector__XXX
 SG_ CAN_TX_TRACK_ANGLE : 12|10@0- (0.1,0) [-51.2|51.1] "" Vector__XXX

BO_ 1322 Target43: 8 Vector__XXX
 SG_ CAN_TX_TRACK_WIDTH : 37|4@0+ (0.5,0) [0|7.5] "" Vector__XXX
 SG_ CAN_TX_TRACK_STATUS : 15|3@0+ (1,0) [0|7] "" Vector__XXX
 SG_ CAN_TX_TRACK_ROLLING_COUNT : 38|1@0+ (1,0) [0|1] "" Vector__XXX
 SG_ CAN_TX_TRACK_RANGE_RATE : 53|14@0- (0.01,0) [-81.92|81.91] "m/s" Vector__XXX
 SG_ CAN_TX_TRACK_RANGE_ACCEL : 33|10@0- (0.05,0) [-25.6|25.55] "m/s^2" Vector__XXX
 SG_ CAN_TX_TRACK_RANGE : 18|11@0+ (0.1,0) [0|204.7] "m" Vector__XXX
 SG_ CAN_TX_TRACK_ONCOMING : 0|1@0+ (1,0) [0|1] "" Vector__XXX
 SG_ CAN_TX_TRACK_MED_RANGE_MODE : 55|2@0+ (1,0) [0|3] "" Vector__XXX
 SG_ CAN_TX_TRACK_LAT_RATE : 7|6@0- (0.25,0) [-8|7.75] "" Vector__XXX
 SG_ CAN_TX_TRACK_GROUPING_CHANGED : 1|1@0+ (1,0) [0|1] "" Vector__XXX
 SG_ CAN_TX_TRACK_BRIDGE_OBJECT : 39|1@0+ (1,0) [0|1] "" Vector__XXX
 SG_ CAN_TX_TRACK_ANGLE : 12|10@0- (0.1,0) [-51.2|51.1] "" Vector__XXX

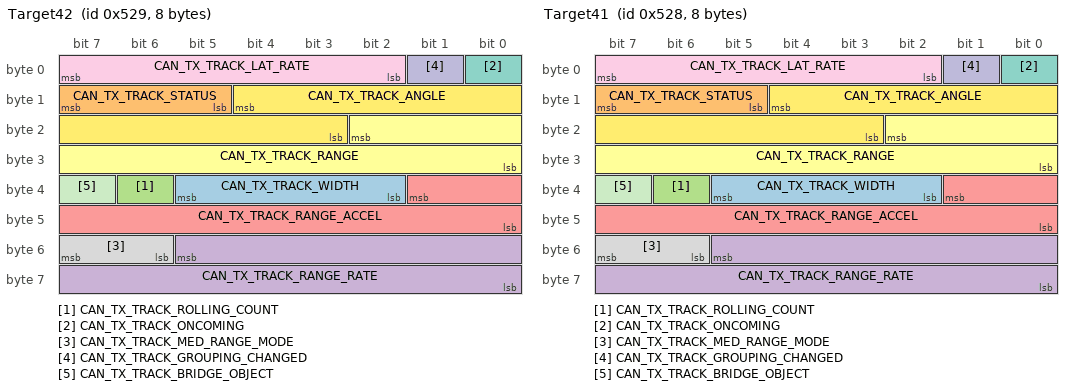
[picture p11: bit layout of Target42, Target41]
BO_ 1321 Target42: 8 Vector__XXX
 SG_ CAN_TX_TRACK_WIDTH : 37|4@0+ (0.5,0) [0|7.5] "" Vector__XXX
 SG_ CAN_TX_TRACK_STATUS : 15|3@0+ (1,0) [0|7] "" Vector__XXX
 SG_ CAN_TX_TRACK_ROLLING_COUNT : 38|1@0+ (1,0) [0|1] "" Vector__XXX
 SG_ CAN_TX_TRACK_RANGE_RATE : 53|14@0- (0.01,0) [-81.92|81.91] "m/s" Vector__XXX
 SG_ CAN_TX_TRACK_RANGE_ACCEL : 33|10@0- (0.05,0) [-25.6|25.55] "m/s^2" Vector__XXX
 SG_ CAN_TX_TRACK_RANGE : 18|11@0+ (0.1,0) [0|204.7] "m" Vector__XXX
 SG_ CAN_TX_TRACK_ONCOMING : 0|1@0+ (1,0) [0|1] "" Vector__XXX
 SG_ CAN_TX_TRACK_MED_RANGE_MODE : 55|2@0+ (1,0) [0|3] "" Vector__XXX
 SG_ CAN_TX_TRACK_LAT_RATE : 7|6@0- (0.25,0) [-8|7.75] "" Vector__XXX
 SG_ CAN_TX_TRACK_GROUPING_CHANGED : 1|1@0+ (1,0) [0|1] "" Vector__XXX
 SG_ CAN_TX_TRACK_BRIDGE_OBJECT : 39|1@0+ (1,0) [0|1] "" Vector__XXX
 SG_ CAN_TX_TRACK_ANGLE : 12|10@0- (0.1,0) [-51.2|51.1] "" Vector__XXX

BO_ 1320 Target41: 8 Vector__XXX
 SG_ CAN_TX_TRACK_WIDTH : 37|4@0+ (0.5,0) [0|7.5] "" Vector__XXX
 SG_ CAN_TX_TRACK_STATUS : 15|3@0+ (1,0) [0|7] "" Vector__XXX
 SG_ CAN_TX_TRACK_ROLLING_COUNT : 38|1@0+ (1,0) [0|1] "" Vector__XXX
 SG_ CAN_TX_TRACK_RANGE_RATE : 53|14@0- (0.01,0) [-81.92|81.91] "m/s" Vector__XXX
 SG_ CAN_TX_TRACK_RANGE_ACCEL : 33|10@0- (0.05,0) [-25.6|25.55] "m/s^2" Vector__XXX
 SG_ CAN_TX_TRACK_RANGE : 18|11@0+ (0.1,0) [0|204.7] "m" Vector__XXX
 SG_ CAN_TX_TRACK_ONCOMING : 0|1@0+ (1,0) [0|1] "" Vector__XXX
 SG_ CAN_TX_TRACK_MED_RANGE_MODE : 55|2@0+ (1,0) [0|3] "" Vector__XXX
 SG_ CAN_TX_TRACK_LAT_RATE : 7|6@0- (0.25,0) [-8|7.75] "" Vector__XXX
 SG_ CAN_TX_TRACK_GROUPING_CHANGED : 1|1@0+ (1,0) [0|1] "" Vector__XXX
 SG_ CAN_TX_TRACK_BRIDGE_OBJECT : 39|1@0+ (1,0) [0|1] "" Vector__XXX
 SG_ CAN_TX_TRACK_ANGLE : 12|10@0- (0.1,0) [-51.2|51.1] "" Vector__XXX

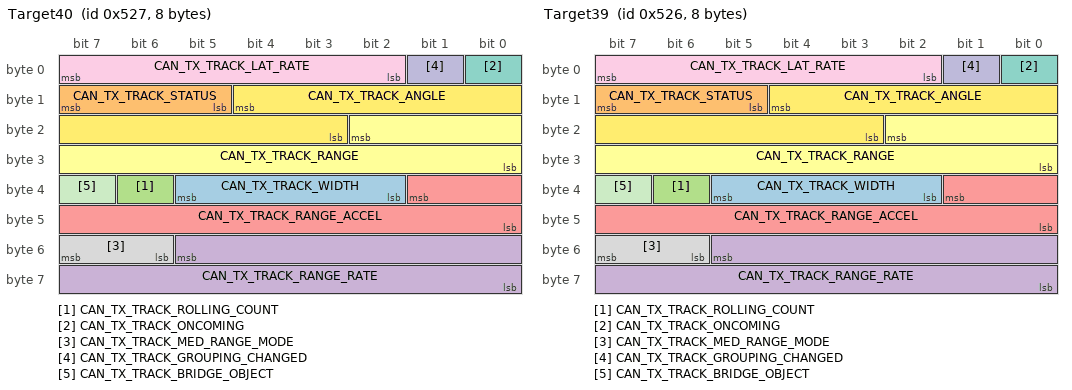
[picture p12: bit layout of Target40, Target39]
BO_ 1319 Target40: 8 Vector__XXX
 SG_ CAN_TX_TRACK_WIDTH : 37|4@0+ (0.5,0) [0|7.5] "" Vector__XXX
 SG_ CAN_TX_TRACK_STATUS : 15|3@0+ (1,0) [0|7] "" Vector__XXX
 SG_ CAN_TX_TRACK_ROLLING_COUNT : 38|1@0+ (1,0) [0|1] "" Vector__XXX
 SG_ CAN_TX_TRACK_RANGE_RATE : 53|14@0- (0.01,0) [-81.92|81.91] "m/s" Vector__XXX
 SG_ CAN_TX_TRACK_RANGE_ACCEL : 33|10@0- (0.05,0) [-25.6|25.55] "m/s^2" Vector__XXX
 SG_ CAN_TX_TRACK_RANGE : 18|11@0+ (0.1,0) [0|204.7] "m" Vector__XXX
 SG_ CAN_TX_TRACK_ONCOMING : 0|1@0+ (1,0) [0|1] "" Vector__XXX
 SG_ CAN_TX_TRACK_MED_RANGE_MODE : 55|2@0+ (1,0) [0|3] "" Vector__XXX
 SG_ CAN_TX_TRACK_LAT_RATE : 7|6@0- (0.25,0) [-8|7.75] "" Vector__XXX
 SG_ CAN_TX_TRACK_GROUPING_CHANGED : 1|1@0+ (1,0) [0|1] "" Vector__XXX
 SG_ CAN_TX_TRACK_BRIDGE_OBJECT : 39|1@0+ (1,0) [0|1] "" Vector__XXX
 SG_ CAN_TX_TRACK_ANGLE : 12|10@0- (0.1,0) [-51.2|51.1] "" Vector__XXX

BO_ 1318 Target39: 8 Vector__XXX
 SG_ CAN_TX_TRACK_WIDTH : 37|4@0+ (0.5,0) [0|7.5] "" Vector__XXX
 SG_ CAN_TX_TRACK_STATUS : 15|3@0+ (1,0) [0|7] "" Vector__XXX
 SG_ CAN_TX_TRACK_ROLLING_COUNT : 38|1@0+ (1,0) [0|1] "" Vector__XXX
 SG_ CAN_TX_TRACK_RANGE_RATE : 53|14@0- (0.01,0) [-81.92|81.91] "m/s" Vector__XXX
 SG_ CAN_TX_TRACK_RANGE_ACCEL : 33|10@0- (0.05,0) [-25.6|25.55] "m/s^2" Vector__XXX
 SG_ CAN_TX_TRACK_RANGE : 18|11@0+ (0.1,0) [0|204.7] "m" Vector__XXX
 SG_ CAN_TX_TRACK_ONCOMING : 0|1@0+ (1,0) [0|1] "" Vector__XXX
 SG_ CAN_TX_TRACK_MED_RANGE_MODE : 55|2@0+ (1,0) [0|3] "" Vector__XXX
 SG_ CAN_TX_TRACK_LAT_RATE : 7|6@0- (0.25,0) [-8|7.75] "" Vector__XXX
 SG_ CAN_TX_TRACK_GROUPING_CHANGED : 1|1@0+ (1,0) [0|1] "" Vector__XXX
 SG_ CAN_TX_TRACK_BRIDGE_OBJECT : 39|1@0+ (1,0) [0|1] "" Vector__XXX
 SG_ CAN_TX_TRACK_ANGLE : 12|10@0- (0.1,0) [-51.2|51.1] "" Vector__XXX

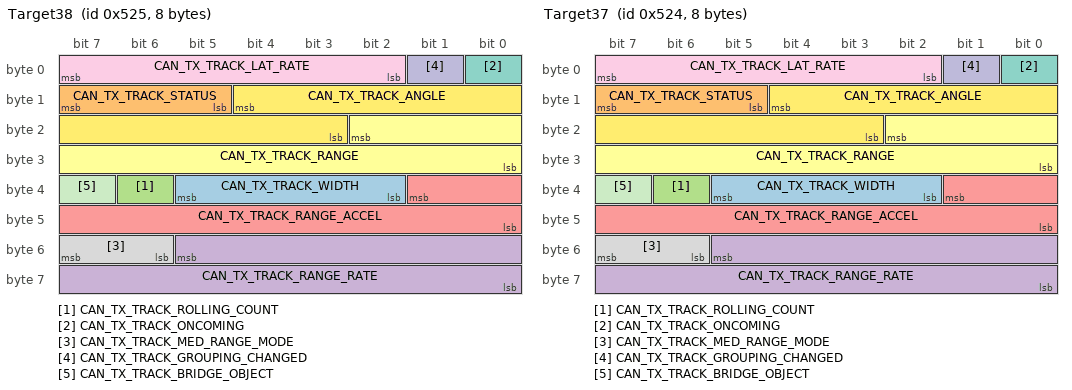
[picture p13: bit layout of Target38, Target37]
BO_ 1317 Target38: 8 Vector__XXX
 SG_ CAN_TX_TRACK_WIDTH : 37|4@0+ (0.5,0) [0|7.5] "" Vector__XXX
 SG_ CAN_TX_TRACK_STATUS : 15|3@0+ (1,0) [0|7] "" Vector__XXX
 SG_ CAN_TX_TRACK_ROLLING_COUNT : 38|1@0+ (1,0) [0|1] "" Vector__XXX
 SG_ CAN_TX_TRACK_RANGE_RATE : 53|14@0- (0.01,0) [-81.92|81.91] "m/s" Vector__XXX
 SG_ CAN_TX_TRACK_RANGE_ACCEL : 33|10@0- (0.05,0) [-25.6|25.55] "m/s^2" Vector__XXX
 SG_ CAN_TX_TRACK_RANGE : 18|11@0+ (0.1,0) [0|204.7] "m" Vector__XXX
 SG_ CAN_TX_TRACK_ONCOMING : 0|1@0+ (1,0) [0|1] "" Vector__XXX
 SG_ CAN_TX_TRACK_MED_RANGE_MODE : 55|2@0+ (1,0) [0|3] "" Vector__XXX
 SG_ CAN_TX_TRACK_LAT_RATE : 7|6@0- (0.25,0) [-8|7.75] "" Vector__XXX
 SG_ CAN_TX_TRACK_GROUPING_CHANGED : 1|1@0+ (1,0) [0|1] "" Vector__XXX
 SG_ CAN_TX_TRACK_BRIDGE_OBJECT : 39|1@0+ (1,0) [0|1] "" Vector__XXX
 SG_ CAN_TX_TRACK_ANGLE : 12|10@0- (0.1,0) [-51.2|51.1] "" Vector__XXX

BO_ 1316 Target37: 8 Vector__XXX
 SG_ CAN_TX_TRACK_WIDTH : 37|4@0+ (0.5,0) [0|7.5] "" Vector__XXX
 SG_ CAN_TX_TRACK_STATUS : 15|3@0+ (1,0) [0|7] "" Vector__XXX
 SG_ CAN_TX_TRACK_ROLLING_COUNT : 38|1@0+ (1,0) [0|1] "" Vector__XXX
 SG_ CAN_TX_TRACK_RANGE_RATE : 53|14@0- (0.01,0) [-81.92|81.91] "m/s" Vector__XXX
 SG_ CAN_TX_TRACK_RANGE_ACCEL : 33|10@0- (0.05,0) [-25.6|25.55] "m/s^2" Vector__XXX
 SG_ CAN_TX_TRACK_RANGE : 18|11@0+ (0.1,0) [0|204.7] "m" Vector__XXX
 SG_ CAN_TX_TRACK_ONCOMING : 0|1@0+ (1,0) [0|1] "" Vector__XXX
 SG_ CAN_TX_TRACK_MED_RANGE_MODE : 55|2@0+ (1,0) [0|3] "" Vector__XXX
 SG_ CAN_TX_TRACK_LAT_RATE : 7|6@0- (0.25,0) [-8|7.75] "" Vector__XXX
 SG_ CAN_TX_TRACK_GROUPING_CHANGED : 1|1@0+ (1,0) [0|1] "" Vector__XXX
 SG_ CAN_TX_TRACK_BRIDGE_OBJECT : 39|1@0+ (1,0) [0|1] "" Vector__XXX
 SG_ CAN_TX_TRACK_ANGLE : 12|10@0- (0.1,0) [-51.2|51.1] "" Vector__XXX

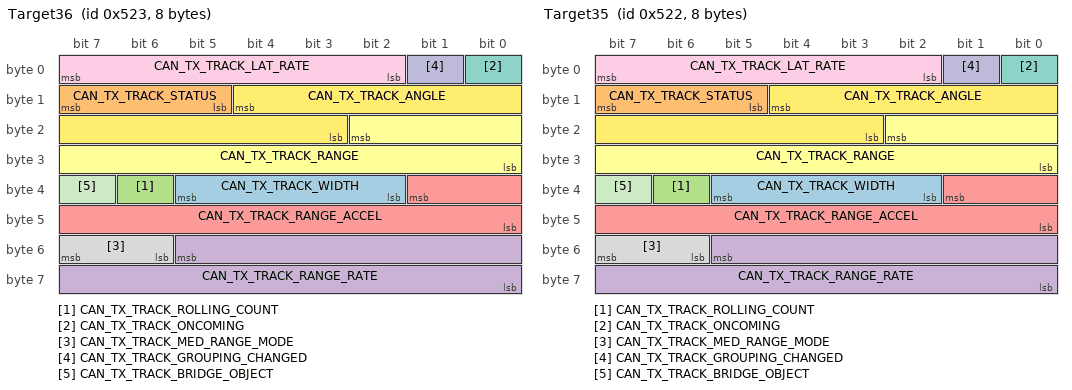
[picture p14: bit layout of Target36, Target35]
BO_ 1315 Target36: 8 Vector__XXX
 SG_ CAN_TX_TRACK_WIDTH : 37|4@0+ (0.5,0) [0|7.5] "" Vector__XXX
 SG_ CAN_TX_TRACK_STATUS : 15|3@0+ (1,0) [0|7] "" Vector__XXX
 SG_ CAN_TX_TRACK_ROLLING_COUNT : 38|1@0+ (1,0) [0|1] "" Vector__XXX
 SG_ CAN_TX_TRACK_RANGE_RATE : 53|14@0- (0.01,0) [-81.92|81.91] "m/s" Vector__XXX
 SG_ CAN_TX_TRACK_RANGE_ACCEL : 33|10@0- (0.05,0) [-25.6|25.55] "m/s^2" Vector__XXX
 SG_ CAN_TX_TRACK_RANGE : 18|11@0+ (0.1,0) [0|204.7] "m" Vector__XXX
 SG_ CAN_TX_TRACK_ONCOMING : 0|1@0+ (1,0) [0|1] "" Vector__XXX
 SG_ CAN_TX_TRACK_MED_RANGE_MODE : 55|2@0+ (1,0) [0|3] "" Vector__XXX
 SG_ CAN_TX_TRACK_LAT_RATE : 7|6@0- (0.25,0) [-8|7.75] "" Vector__XXX
 SG_ CAN_TX_TRACK_GROUPING_CHANGED : 1|1@0+ (1,0) [0|1] "" Vector__XXX
 SG_ CAN_TX_TRACK_BRIDGE_OBJECT : 39|1@0+ (1,0) [0|1] "" Vector__XXX
 SG_ CAN_TX_TRACK_ANGLE : 12|10@0- (0.1,0) [-51.2|51.1] "" Vector__XXX

BO_ 1314 Target35: 8 Vector__XXX
 SG_ CAN_TX_TRACK_WIDTH : 37|4@0+ (0.5,0) [0|7.5] "" Vector__XXX
 SG_ CAN_TX_TRACK_STATUS : 15|3@0+ (1,0) [0|7] "" Vector__XXX
 SG_ CAN_TX_TRACK_ROLLING_COUNT : 38|1@0+ (1,0) [0|1] "" Vector__XXX
 SG_ CAN_TX_TRACK_RANGE_RATE : 53|14@0- (0.01,0) [-81.92|81.91] "m/s" Vector__XXX
 SG_ CAN_TX_TRACK_RANGE_ACCEL : 33|10@0- (0.05,0) [-25.6|25.55] "m/s^2" Vector__XXX
 SG_ CAN_TX_TRACK_RANGE : 18|11@0+ (0.1,0) [0|204.7] "m" Vector__XXX
 SG_ CAN_TX_TRACK_ONCOMING : 0|1@0+ (1,0) [0|1] "" Vector__XXX
 SG_ CAN_TX_TRACK_MED_RANGE_MODE : 55|2@0+ (1,0) [0|3] "" Vector__XXX
 SG_ CAN_TX_TRACK_LAT_RATE : 7|6@0- (0.25,0) [-8|7.75] "" Vector__XXX
 SG_ CAN_TX_TRACK_GROUPING_CHANGED : 1|1@0+ (1,0) [0|1] "" Vector__XXX
 SG_ CAN_TX_TRACK_BRIDGE_OBJECT : 39|1@0+ (1,0) [0|1] "" Vector__XXX
 SG_ CAN_TX_TRACK_ANGLE : 12|10@0- (0.1,0) [-51.2|51.1] "" Vector__XXX

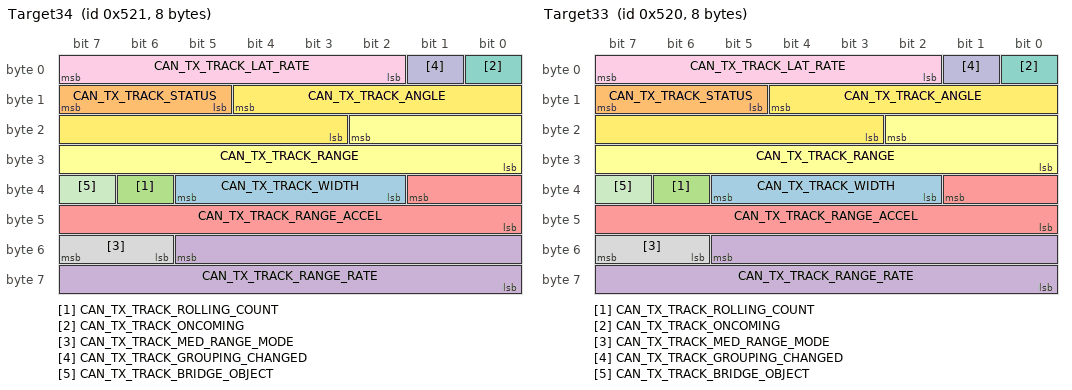
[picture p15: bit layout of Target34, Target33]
BO_ 1313 Target34: 8 Vector__XXX
 SG_ CAN_TX_TRACK_WIDTH : 37|4@0+ (0.5,0) [0|7.5] "" Vector__XXX
 SG_ CAN_TX_TRACK_STATUS : 15|3@0+ (1,0) [0|7] "" Vector__XXX
 SG_ CAN_TX_TRACK_ROLLING_COUNT : 38|1@0+ (1,0) [0|1] "" Vector__XXX
 SG_ CAN_TX_TRACK_RANGE_RATE : 53|14@0- (0.01,0) [-81.92|81.91] "m/s" Vector__XXX
 SG_ CAN_TX_TRACK_RANGE_ACCEL : 33|10@0- (0.05,0) [-25.6|25.55] "m/s^2" Vector__XXX
 SG_ CAN_TX_TRACK_RANGE : 18|11@0+ (0.1,0) [0|204.7] "m" Vector__XXX
 SG_ CAN_TX_TRACK_ONCOMING : 0|1@0+ (1,0) [0|1] "" Vector__XXX
 SG_ CAN_TX_TRACK_MED_RANGE_MODE : 55|2@0+ (1,0) [0|3] "" Vector__XXX
 SG_ CAN_TX_TRACK_LAT_RATE : 7|6@0- (0.25,0) [-8|7.75] "" Vector__XXX
 SG_ CAN_TX_TRACK_GROUPING_CHANGED : 1|1@0+ (1,0) [0|1] "" Vector__XXX
 SG_ CAN_TX_TRACK_BRIDGE_OBJECT : 39|1@0+ (1,0) [0|1] "" Vector__XXX
 SG_ CAN_TX_TRACK_ANGLE : 12|10@0- (0.1,0) [-51.2|51.1] "" Vector__XXX

BO_ 1312 Target33: 8 Vector__XXX
 SG_ CAN_TX_TRACK_WIDTH : 37|4@0+ (0.5,0) [0|7.5] "" Vector__XXX
 SG_ CAN_TX_TRACK_STATUS : 15|3@0+ (1,0) [0|7] "" Vector__XXX
 SG_ CAN_TX_TRACK_ROLLING_COUNT : 38|1@0+ (1,0) [0|1] "" Vector__XXX
 SG_ CAN_TX_TRACK_RANGE_RATE : 53|14@0- (0.01,0) [-81.92|81.91] "m/s" Vector__XXX
 SG_ CAN_TX_TRACK_RANGE_ACCEL : 33|10@0- (0.05,0) [-25.6|25.55] "m/s^2" Vector__XXX
 SG_ CAN_TX_TRACK_RANGE : 18|11@0+ (0.1,0) [0|204.7] "m" Vector__XXX
 SG_ CAN_TX_TRACK_ONCOMING : 0|1@0+ (1,0) [0|1] "" Vector__XXX
 SG_ CAN_TX_TRACK_MED_RANGE_MODE : 55|2@0+ (1,0) [0|3] "" Vector__XXX
 SG_ CAN_TX_TRACK_LAT_RATE : 7|6@0- (0.25,0) [-8|7.75] "" Vector__XXX
 SG_ CAN_TX_TRACK_GROUPING_CHANGED : 1|1@0+ (1,0) [0|1] "" Vector__XXX
 SG_ CAN_TX_TRACK_BRIDGE_OBJECT : 39|1@0+ (1,0) [0|1] "" Vector__XXX
 SG_ CAN_TX_TRACK_ANGLE : 12|10@0- (0.1,0) [-51.2|51.1] "" Vector__XXX

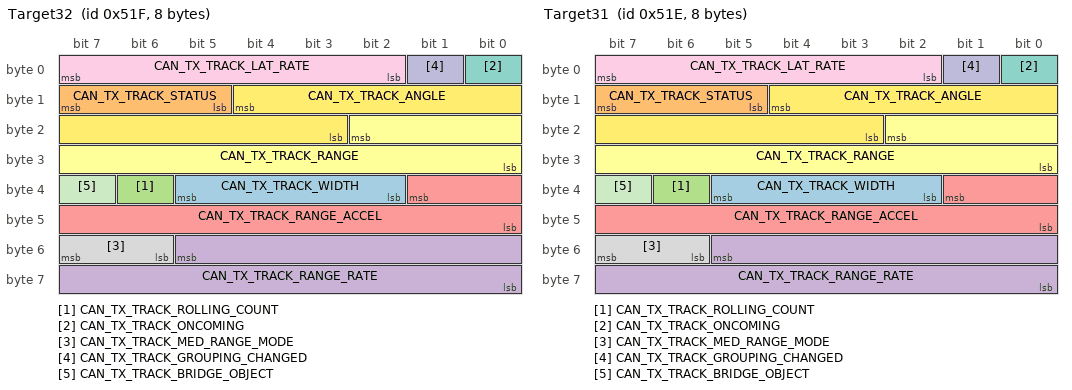
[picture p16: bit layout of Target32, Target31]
BO_ 1311 Target32: 8 Vector__XXX
 SG_ CAN_TX_TRACK_WIDTH : 37|4@0+ (0.5,0) [0|7.5] "" Vector__XXX
 SG_ CAN_TX_TRACK_STATUS : 15|3@0+ (1,0) [0|7] "" Vector__XXX
 SG_ CAN_TX_TRACK_ROLLING_COUNT : 38|1@0+ (1,0) [0|1] "" Vector__XXX
 SG_ CAN_TX_TRACK_RANGE_RATE : 53|14@0- (0.01,0) [-81.92|81.91] "m/s" Vector__XXX
 SG_ CAN_TX_TRACK_RANGE_ACCEL : 33|10@0- (0.05,0) [-25.6|25.55] "m/s^2" Vector__XXX
 SG_ CAN_TX_TRACK_RANGE : 18|11@0+ (0.1,0) [0|204.7] "m" Vector__XXX
 SG_ CAN_TX_TRACK_ONCOMING : 0|1@0+ (1,0) [0|1] "" Vector__XXX
 SG_ CAN_TX_TRACK_MED_RANGE_MODE : 55|2@0+ (1,0) [0|3] "" Vector__XXX
 SG_ CAN_TX_TRACK_LAT_RATE : 7|6@0- (0.25,0) [-8|7.75] "" Vector__XXX
 SG_ CAN_TX_TRACK_GROUPING_CHANGED : 1|1@0+ (1,0) [0|1] "" Vector__XXX
 SG_ CAN_TX_TRACK_BRIDGE_OBJECT : 39|1@0+ (1,0) [0|1] "" Vector__XXX
 SG_ CAN_TX_TRACK_ANGLE : 12|10@0- (0.1,0) [-51.2|51.1] "" Vector__XXX

BO_ 1310 Target31: 8 Vector__XXX
 SG_ CAN_TX_TRACK_WIDTH : 37|4@0+ (0.5,0) [0|7.5] "" Vector__XXX
 SG_ CAN_TX_TRACK_STATUS : 15|3@0+ (1,0) [0|7] "" Vector__XXX
 SG_ CAN_TX_TRACK_ROLLING_COUNT : 38|1@0+ (1,0) [0|1] "" Vector__XXX
 SG_ CAN_TX_TRACK_RANGE_RATE : 53|14@0- (0.01,0) [-81.92|81.91] "m/s" Vector__XXX
 SG_ CAN_TX_TRACK_RANGE_ACCEL : 33|10@0- (0.05,0) [-25.6|25.55] "m/s^2" Vector__XXX
 SG_ CAN_TX_TRACK_RANGE : 18|11@0+ (0.1,0) [0|204.7] "m" Vector__XXX
 SG_ CAN_TX_TRACK_ONCOMING : 0|1@0+ (1,0) [0|1] "" Vector__XXX
 SG_ CAN_TX_TRACK_MED_RANGE_MODE : 55|2@0+ (1,0) [0|3] "" Vector__XXX
 SG_ CAN_TX_TRACK_LAT_RATE : 7|6@0- (0.25,0) [-8|7.75] "" Vector__XXX
 SG_ CAN_TX_TRACK_GROUPING_CHANGED : 1|1@0+ (1,0) [0|1] "" Vector__XXX
 SG_ CAN_TX_TRACK_BRIDGE_OBJECT : 39|1@0+ (1,0) [0|1] "" Vector__XXX
 SG_ CAN_TX_TRACK_ANGLE : 12|10@0- (0.1,0) [-51.2|51.1] "" Vector__XXX

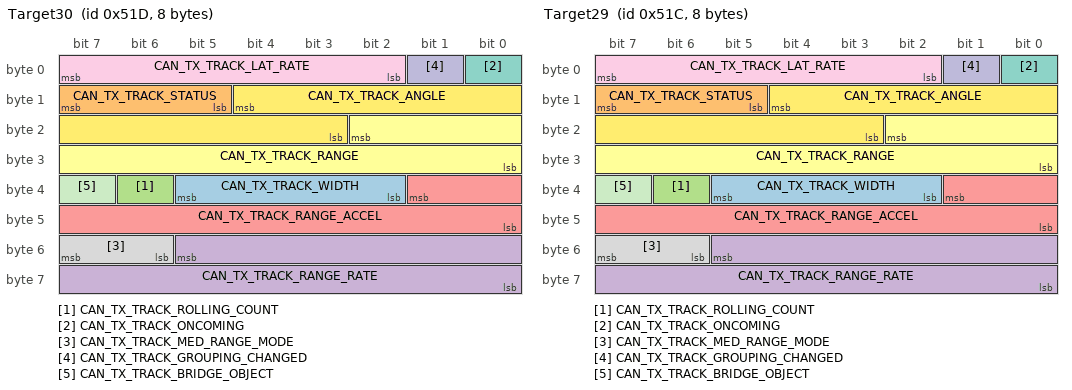
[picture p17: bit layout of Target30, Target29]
BO_ 1309 Target30: 8 Vector__XXX
 SG_ CAN_TX_TRACK_WIDTH : 37|4@0+ (0.5,0) [0|7.5] "" Vector__XXX
 SG_ CAN_TX_TRACK_STATUS : 15|3@0+ (1,0) [0|7] "" Vector__XXX
 SG_ CAN_TX_TRACK_ROLLING_COUNT : 38|1@0+ (1,0) [0|1] "" Vector__XXX
 SG_ CAN_TX_TRACK_RANGE_RATE : 53|14@0- (0.01,0) [-81.92|81.91] "m/s" Vector__XXX
 SG_ CAN_TX_TRACK_RANGE_ACCEL : 33|10@0- (0.05,0) [-25.6|25.55] "m/s^2" Vector__XXX
 SG_ CAN_TX_TRACK_RANGE : 18|11@0+ (0.1,0) [0|204.7] "m" Vector__XXX
 SG_ CAN_TX_TRACK_ONCOMING : 0|1@0+ (1,0) [0|1] "" Vector__XXX
 SG_ CAN_TX_TRACK_MED_RANGE_MODE : 55|2@0+ (1,0) [0|3] "" Vector__XXX
 SG_ CAN_TX_TRACK_LAT_RATE : 7|6@0- (0.25,0) [-8|7.75] "" Vector__XXX
 SG_ CAN_TX_TRACK_GROUPING_CHANGED : 1|1@0+ (1,0) [0|1] "" Vector__XXX
 SG_ CAN_TX_TRACK_BRIDGE_OBJECT : 39|1@0+ (1,0) [0|1] "" Vector__XXX
 SG_ CAN_TX_TRACK_ANGLE : 12|10@0- (0.1,0) [-51.2|51.1] "" Vector__XXX

BO_ 1308 Target29: 8 Vector__XXX
 SG_ CAN_TX_TRACK_WIDTH : 37|4@0+ (0.5,0) [0|7.5] "" Vector__XXX
 SG_ CAN_TX_TRACK_STATUS : 15|3@0+ (1,0) [0|7] "" Vector__XXX
 SG_ CAN_TX_TRACK_ROLLING_COUNT : 38|1@0+ (1,0) [0|1] "" Vector__XXX
 SG_ CAN_TX_TRACK_RANGE_RATE : 53|14@0- (0.01,0) [-81.92|81.91] "m/s" Vector__XXX
 SG_ CAN_TX_TRACK_RANGE_ACCEL : 33|10@0- (0.05,0) [-25.6|25.55] "m/s^2" Vector__XXX
 SG_ CAN_TX_TRACK_RANGE : 18|11@0+ (0.1,0) [0|204.7] "m" Vector__XXX
 SG_ CAN_TX_TRACK_ONCOMING : 0|1@0+ (1,0) [0|1] "" Vector__XXX
 SG_ CAN_TX_TRACK_MED_RANGE_MODE : 55|2@0+ (1,0) [0|3] "" Vector__XXX
 SG_ CAN_TX_TRACK_LAT_RATE : 7|6@0- (0.25,0) [-8|7.75] "" Vector__XXX
 SG_ CAN_TX_TRACK_GROUPING_CHANGED : 1|1@0+ (1,0) [0|1] "" Vector__XXX
 SG_ CAN_TX_TRACK_BRIDGE_OBJECT : 39|1@0+ (1,0) [0|1] "" Vector__XXX
 SG_ CAN_TX_TRACK_ANGLE : 12|10@0- (0.1,0) [-51.2|51.1] "" Vector__XXX

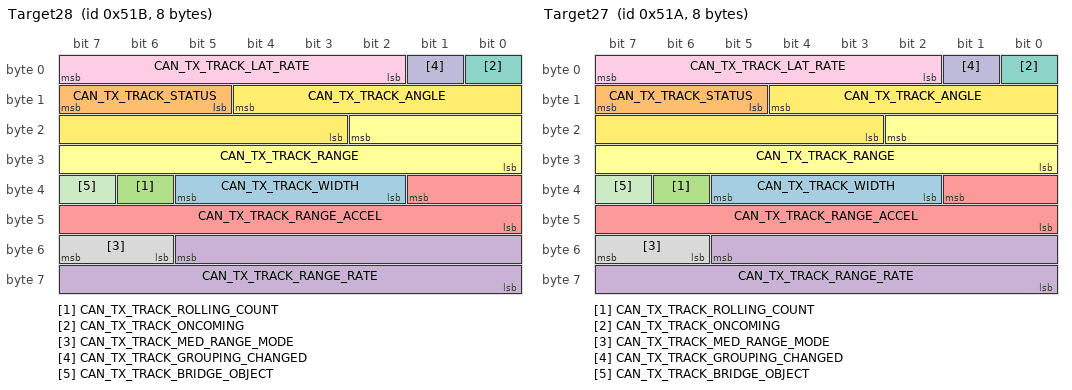
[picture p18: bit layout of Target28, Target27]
BO_ 1307 Target28: 8 Vector__XXX
 SG_ CAN_TX_TRACK_WIDTH : 37|4@0+ (0.5,0) [0|7.5] "" Vector__XXX
 SG_ CAN_TX_TRACK_STATUS : 15|3@0+ (1,0) [0|7] "" Vector__XXX
 SG_ CAN_TX_TRACK_ROLLING_COUNT : 38|1@0+ (1,0) [0|1] "" Vector__XXX
 SG_ CAN_TX_TRACK_RANGE_RATE : 53|14@0- (0.01,0) [-81.92|81.91] "m/s" Vector__XXX
 SG_ CAN_TX_TRACK_RANGE_ACCEL : 33|10@0- (0.05,0) [-25.6|25.55] "m/s^2" Vector__XXX
 SG_ CAN_TX_TRACK_RANGE : 18|11@0+ (0.1,0) [0|204.7] "m" Vector__XXX
 SG_ CAN_TX_TRACK_ONCOMING : 0|1@0+ (1,0) [0|1] "" Vector__XXX
 SG_ CAN_TX_TRACK_MED_RANGE_MODE : 55|2@0+ (1,0) [0|3] "" Vector__XXX
 SG_ CAN_TX_TRACK_LAT_RATE : 7|6@0- (0.25,0) [-8|7.75] "" Vector__XXX
 SG_ CAN_TX_TRACK_GROUPING_CHANGED : 1|1@0+ (1,0) [0|1] "" Vector__XXX
 SG_ CAN_TX_TRACK_BRIDGE_OBJECT : 39|1@0+ (1,0) [0|1] "" Vector__XXX
 SG_ CAN_TX_TRACK_ANGLE : 12|10@0- (0.1,0) [-51.2|51.1] "" Vector__XXX

BO_ 1306 Target27: 8 Vector__XXX
 SG_ CAN_TX_TRACK_WIDTH : 37|4@0+ (0.5,0) [0|7.5] "" Vector__XXX
 SG_ CAN_TX_TRACK_STATUS : 15|3@0+ (1,0) [0|7] "" Vector__XXX
 SG_ CAN_TX_TRACK_ROLLING_COUNT : 38|1@0+ (1,0) [0|1] "" Vector__XXX
 SG_ CAN_TX_TRACK_RANGE_RATE : 53|14@0- (0.01,0) [-81.92|81.91] "m/s" Vector__XXX
 SG_ CAN_TX_TRACK_RANGE_ACCEL : 33|10@0- (0.05,0) [-25.6|25.55] "m/s^2" Vector__XXX
 SG_ CAN_TX_TRACK_RANGE : 18|11@0+ (0.1,0) [0|204.7] "m" Vector__XXX
 SG_ CAN_TX_TRACK_ONCOMING : 0|1@0+ (1,0) [0|1] "" Vector__XXX
 SG_ CAN_TX_TRACK_MED_RANGE_MODE : 55|2@0+ (1,0) [0|3] "" Vector__XXX
 SG_ CAN_TX_TRACK_LAT_RATE : 7|6@0- (0.25,0) [-8|7.75] "" Vector__XXX
 SG_ CAN_TX_TRACK_GROUPING_CHANGED : 1|1@0+ (1,0) [0|1] "" Vector__XXX
 SG_ CAN_TX_TRACK_BRIDGE_OBJECT : 39|1@0+ (1,0) [0|1] "" Vector__XXX
 SG_ CAN_TX_TRACK_ANGLE : 12|10@0- (0.1,0) [-51.2|51.1] "" Vector__XXX

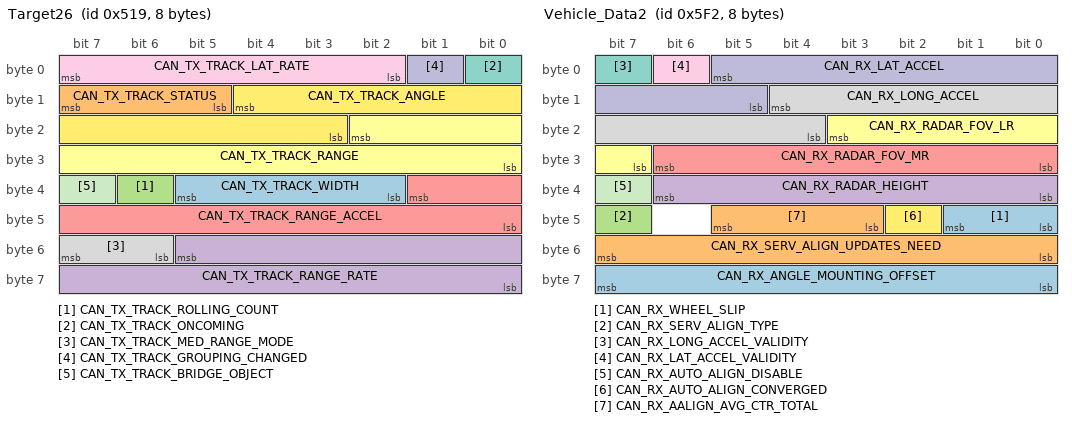
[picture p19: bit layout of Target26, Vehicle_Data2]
BO_ 1305 Target26: 8 Vector__XXX
 SG_ CAN_TX_TRACK_WIDTH : 37|4@0+ (0.5,0) [0|7.5] "" Vector__XXX
 SG_ CAN_TX_TRACK_STATUS : 15|3@0+ (1,0) [0|7] "" Vector__XXX
 SG_ CAN_TX_TRACK_ROLLING_COUNT : 38|1@0+ (1,0) [0|1] "" Vector__XXX
 SG_ CAN_TX_TRACK_RANGE_RATE : 53|14@0- (0.01,0) [-81.92|81.91] "m/s" Vector__XXX
 SG_ CAN_TX_TRACK_RANGE_ACCEL : 33|10@0- (0.05,0) [-25.6|25.55] "m/s^2" Vector__XXX
 SG_ CAN_TX_TRACK_RANGE : 18|11@0+ (0.1,0) [0|204.7] "m" Vector__XXX
 SG_ CAN_TX_TRACK_ONCOMING : 0|1@0+ (1,0) [0|1] "" Vector__XXX
 SG_ CAN_TX_TRACK_MED_RANGE_MODE : 55|2@0+ (1,0) [0|3] "" Vector__XXX
 SG_ CAN_TX_TRACK_LAT_RATE : 7|6@0- (0.25,0) [-8|7.75] "" Vector__XXX
 SG_ CAN_TX_TRACK_GROUPING_CHANGED : 1|1@0+ (1,0) [0|1] "" Vector__XXX
 SG_ CAN_TX_TRACK_BRIDGE_OBJECT : 39|1@0+ (1,0) [0|1] "" Vector__XXX
 SG_ CAN_TX_TRACK_ANGLE : 12|10@0- (0.1,0) [-51.2|51.1] "" Vector__XXX

BO_ 1304 Target25: 8 Vector__XXX
 SG_ CAN_TX_TRACK_WIDTH : 37|4@0+ (0.5,0) [0|7.5] "" Vector__XXX
 SG_ CAN_TX_TRACK_STATUS : 15|3@0+ (1,0) [0|7] "" Vector__XXX
 SG_ CAN_TX_TRACK_ROLLING_COUNT : 38|1@0+ (1,0) [0|1] "" Vector__XXX
 SG_ CAN_TX_TRACK_RANGE_RATE : 53|14@0- (0.01,0) [-81.92|81.91] "m/s" Vector__XXX
 SG_ CAN_TX_TRACK_RANGE_ACCEL : 33|10@0- (0.05,0) [-25.6|25.55] "m/s^2" Vector__XXX
 SG_ CAN_TX_TRACK_RANGE : 18|11@0+ (0.1,0) [0|204.7] "m" Vector__XXX
 SG_ CAN_TX_TRACK_ONCOMING : 0|1@0+ (1,0) [0|1] "" Vector__XXX
 SG_ CAN_TX_TRACK_MED_RANGE_MODE : 55|2@0+ (1,0) [0|3] "" Vector__XXX
 SG_ CAN_TX_TRACK_LAT_RATE : 7|6@0- (0.25,0) [-8|7.75] "" Vector__XXX
 SG_ CAN_TX_TRACK_GROUPING_CHANGED : 1|1@0+ (1,0) [0|1] "" Vector__XXX
 SG_ CAN_TX_TRACK_BRIDGE_OBJECT : 39|1@0+ (1,0) [0|1] "" Vector__XXX
 SG_ CAN_TX_TRACK_ANGLE : 12|10@0- (0.1,0) [-51.2|51.1] "" Vector__XXX

BO_ 1303 Target24: 8 Vector__XXX
 SG_ CAN_TX_TRACK_WIDTH : 37|4@0+ (0.5,0) [0|7.5] "" Vector__XXX
 SG_ CAN_TX_TRACK_STATUS : 15|3@0+ (1,0) [0|7] "" Vector__XXX
 SG_ CAN_TX_TRACK_ROLLING_COUNT : 38|1@0+ (1,0) [0|1] "" Vector__XXX
 SG_ CAN_TX_TRACK_RANGE_RATE : 53|14@0- (0.01,0) [-81.92|81.91] "m/s" Vector__XXX
 SG_ CAN_TX_TRACK_RANGE_ACCEL : 33|10@0- (0.05,0) [-25.6|25.55] "m/s^2" Vector__XXX
 SG_ CAN_TX_TRACK_RANGE : 18|11@0+ (0.1,0) [0|204.7] "m" Vector__XXX
 SG_ CAN_TX_TRACK_ONCOMING : 0|1@0+ (1,0) [0|1] "" Vector__XXX
 SG_ CAN_TX_TRACK_MED_RANGE_MODE : 55|2@0+ (1,0) [0|3] "" Vector__XXX
 SG_ CAN_TX_TRACK_LAT_RATE : 7|6@0- (0.25,0) [-8|7.75] "" Vector__XXX
 SG_ CAN_TX_TRACK_GROUPING_CHANGED : 1|1@0+ (1,0) [0|1] "" Vector__XXX
 SG_ CAN_TX_TRACK_BRIDGE_OBJECT : 39|1@0+ (1,0) [0|1] "" Vector__XXX
 SG_ CAN_TX_TRACK_ANGLE : 12|10@0- (0.1,0) [-51.2|51.1] "" Vector__XXX

BO_ 1302 Target23: 8 Vector__XXX
 SG_ CAN_TX_TRACK_WIDTH : 37|4@0+ (0.5,0) [0|7.5] "" Vector__XXX
 SG_ CAN_TX_TRACK_STATUS : 15|3@0+ (1,0) [0|7] "" Vector__XXX
 SG_ CAN_TX_TRACK_ROLLING_COUNT : 38|1@0+ (1,0) [0|1] "" Vector__XXX
 SG_ CAN_TX_TRACK_RANGE_RATE : 53|14@0- (0.01,0) [-81.92|81.91] "m/s" Vector__XXX
 SG_ CAN_TX_TRACK_RANGE_ACCEL : 33|10@0- (0.05,0) [-25.6|25.55] "m/s^2" Vector__XXX
 SG_ CAN_TX_TRACK_RANGE : 18|11@0+ (0.1,0) [0|204.7] "m" Vector__XXX
 SG_ CAN_TX_TRACK_ONCOMING : 0|1@0+ (1,0) [0|1] "" Vector__XXX
 SG_ CAN_TX_TRACK_MED_RANGE_MODE : 55|2@0+ (1,0) [0|3] "" Vector__XXX
 SG_ CAN_TX_TRACK_LAT_RATE : 7|6@0- (0.25,0) [-8|7.75] "" Vector__XXX
 SG_ CAN_TX_TRACK_GROUPING_CHANGED : 1|1@0+ (1,0) [0|1] "" Vector__XXX
 SG_ CAN_TX_TRACK_BRIDGE_OBJECT : 39|1@0+ (1,0) [0|1] "" Vector__XXX
 SG_ CAN_TX_TRACK_ANGLE : 12|10@0- (0.1,0) [-51.2|51.1] "" Vector__XXX

BO_ 1301 Target22: 8 Vector__XXX
 SG_ CAN_TX_TRACK_WIDTH : 37|4@0+ (0.5,0) [0|7.5] "" Vector__XXX
 SG_ CAN_TX_TRACK_STATUS : 15|3@0+ (1,0) [0|7] "" Vector__XXX
 SG_ CAN_TX_TRACK_ROLLING_COUNT : 38|1@0+ (1,0) [0|1] "" Vector__XXX
 SG_ CAN_TX_TRACK_RANGE_RATE : 53|14@0- (0.01,0) [-81.92|81.91] "m/s" Vector__XXX
 SG_ CAN_TX_TRACK_RANGE_ACCEL : 33|10@0- (0.05,0) [-25.6|25.55] "m/s^2" Vector__XXX
 SG_ CAN_TX_TRACK_RANGE : 18|11@0+ (0.1,0) [0|204.7] "m" Vector__XXX
 SG_ CAN_TX_TRACK_ONCOMING : 0|1@0+ (1,0) [0|1] "" Vector__XXX
 SG_ CAN_TX_TRACK_MED_RANGE_MODE : 55|2@0+ (1,0) [0|3] "" Vector__XXX
 SG_ CAN_TX_TRACK_LAT_RATE : 7|6@0- (0.25,0) [-8|7.75] "" Vector__XXX
 SG_ CAN_TX_TRACK_GROUPING_CHANGED : 1|1@0+ (1,0) [0|1] "" Vector__XXX
 SG_ CAN_TX_TRACK_BRIDGE_OBJECT : 39|1@0+ (1,0) [0|1] "" Vector__XXX
 SG_ CAN_TX_TRACK_ANGLE : 12|10@0- (0.1,0) [-51.2|51.1] "" Vector__XXX

BO_ 1300 Target21: 8 Vector__XXX
 SG_ CAN_TX_TRACK_WIDTH : 37|4@0+ (0.5,0) [0|7.5] "" Vector__XXX
 SG_ CAN_TX_TRACK_STATUS : 15|3@0+ (1,0) [0|7] "" Vector__XXX
 SG_ CAN_TX_TRACK_ROLLING_COUNT : 38|1@0+ (1,0) [0|1] "" Vector__XXX
 SG_ CAN_TX_TRACK_RANGE_RATE : 53|14@0- (0.01,0) [-81.92|81.91] "m/s" Vector__XXX
 SG_ CAN_TX_TRACK_RANGE_ACCEL : 33|10@0- (0.05,0) [-25.6|25.55] "m/s^2" Vector__XXX
 SG_ CAN_TX_TRACK_RANGE : 18|11@0+ (0.1,0) [0|204.7] "m" Vector__XXX
 SG_ CAN_TX_TRACK_ONCOMING : 0|1@0+ (1,0) [0|1] "" Vector__XXX
 SG_ CAN_TX_TRACK_MED_RANGE_MODE : 55|2@0+ (1,0) [0|3] "" Vector__XXX
 SG_ CAN_TX_TRACK_LAT_RATE : 7|6@0- (0.25,0) [-8|7.75] "" Vector__XXX
 SG_ CAN_TX_TRACK_GROUPING_CHANGED : 1|1@0+ (1,0) [0|1] "" Vector__XXX
 SG_ CAN_TX_TRACK_BRIDGE_OBJECT : 39|1@0+ (1,0) [0|1] "" Vector__XXX
 SG_ CAN_TX_TRACK_ANGLE : 12|10@0- (0.1,0) [-51.2|51.1] "" Vector__XXX

BO_ 1299 Target20: 8 Vector__XXX
 SG_ CAN_TX_TRACK_WIDTH : 37|4@0+ (0.5,0) [0|7.5] "" Vector__XXX
 SG_ CAN_TX_TRACK_STATUS : 15|3@0+ (1,0) [0|7] "" Vector__XXX
 SG_ CAN_TX_TRACK_ROLLING_COUNT : 38|1@0+ (1,0) [0|1] "" Vector__XXX
 SG_ CAN_TX_TRACK_RANGE_RATE : 53|14@0- (0.01,0) [-81.92|81.91] "m/s" Vector__XXX
 SG_ CAN_TX_TRACK_RANGE_ACCEL : 33|10@0- (0.05,0) [-25.6|25.55] "m/s^2" Vector__XXX
 SG_ CAN_TX_TRACK_RANGE : 18|11@0+ (0.1,0) [0|204.7] "m" Vector__XXX
 SG_ CAN_TX_TRACK_ONCOMING : 0|1@0+ (1,0) [0|1] "" Vector__XXX
 SG_ CAN_TX_TRACK_MED_RANGE_MODE : 55|2@0+ (1,0) [0|3] "" Vector__XXX
 SG_ CAN_TX_TRACK_LAT_RATE : 7|6@0- (0.25,0) [-8|7.75] "" Vector__XXX
 SG_ CAN_TX_TRACK_GROUPING_CHANGED : 1|1@0+ (1,0) [0|1] "" Vector__XXX
 SG_ CAN_TX_TRACK_BRIDGE_OBJECT : 39|1@0+ (1,0) [0|1] "" Vector__XXX
 SG_ CAN_TX_TRACK_ANGLE : 12|10@0- (0.1,0) [-51.2|51.1] "" Vector__XXX

BO_ 1298 Target19: 8 Vector__XXX
 SG_ CAN_TX_TRACK_WIDTH : 37|4@0+ (0.5,0) [0|7.5] "" Vector__XXX
 SG_ CAN_TX_TRACK_STATUS : 15|3@0+ (1,0) [0|7] "" Vector__XXX
 SG_ CAN_TX_TRACK_ROLLING_COUNT : 38|1@0+ (1,0) [0|1] "" Vector__XXX
 SG_ CAN_TX_TRACK_RANGE_RATE : 53|14@0- (0.01,0) [-81.92|81.91] "m/s" Vector__XXX
 SG_ CAN_TX_TRACK_RANGE_ACCEL : 33|10@0- (0.05,0) [-25.6|25.55] "m/s^2" Vector__XXX
 SG_ CAN_TX_TRACK_RANGE : 18|11@0+ (0.1,0) [0|204.7] "m" Vector__XXX
 SG_ CAN_TX_TRACK_ONCOMING : 0|1@0+ (1,0) [0|1] "" Vector__XXX
 SG_ CAN_TX_TRACK_MED_RANGE_MODE : 55|2@0+ (1,0) [0|3] "" Vector__XXX
 SG_ CAN_TX_TRACK_LAT_RATE : 7|6@0- (0.25,0) [-8|7.75] "" Vector__XXX
 SG_ CAN_TX_TRACK_GROUPING_CHANGED : 1|1@0+ (1,0) [0|1] "" Vector__XXX
 SG_ CAN_TX_TRACK_BRIDGE_OBJECT : 39|1@0+ (1,0) [0|1] "" Vector__XXX
 SG_ CAN_TX_TRACK_ANGLE : 12|10@0- (0.1,0) [-51.2|51.1] "" Vector__XXX

BO_ 1297 Target18: 8 Vector__XXX
 SG_ CAN_TX_TRACK_WIDTH : 37|4@0+ (0.5,0) [0|7.5] "" Vector__XXX
 SG_ CAN_TX_TRACK_STATUS : 15|3@0+ (1,0) [0|7] "" Vector__XXX
 SG_ CAN_TX_TRACK_ROLLING_COUNT : 38|1@0+ (1,0) [0|1] "" Vector__XXX
 SG_ CAN_TX_TRACK_RANGE_RATE : 53|14@0- (0.01,0) [-81.92|81.91] "m/s" Vector__XXX
 SG_ CAN_TX_TRACK_RANGE_ACCEL : 33|10@0- (0.05,0) [-25.6|25.55] "m/s^2" Vector__XXX
 SG_ CAN_TX_TRACK_RANGE : 18|11@0+ (0.1,0) [0|204.7] "m" Vector__XXX
 SG_ CAN_TX_TRACK_ONCOMING : 0|1@0+ (1,0) [0|1] "" Vector__XXX
 SG_ CAN_TX_TRACK_MED_RANGE_MODE : 55|2@0+ (1,0) [0|3] "" Vector__XXX
 SG_ CAN_TX_TRACK_LAT_RATE : 7|6@0- (0.25,0) [-8|7.75] "" Vector__XXX
 SG_ CAN_TX_TRACK_GROUPING_CHANGED : 1|1@0+ (1,0) [0|1] "" Vector__XXX
 SG_ CAN_TX_TRACK_BRIDGE_OBJECT : 39|1@0+ (1,0) [0|1] "" Vector__XXX
 SG_ CAN_TX_TRACK_ANGLE : 12|10@0- (0.1,0) [-51.2|51.1] "" Vector__XXX

BO_ 1296 Target17: 8 Vector__XXX
 SG_ CAN_TX_TRACK_WIDTH : 37|4@0+ (0.5,0) [0|7.5] "" Vector__XXX
 SG_ CAN_TX_TRACK_STATUS : 15|3@0+ (1,0) [0|7] "" Vector__XXX
 SG_ CAN_TX_TRACK_ROLLING_COUNT : 38|1@0+ (1,0) [0|1] "" Vector__XXX
 SG_ CAN_TX_TRACK_RANGE_RATE : 53|14@0- (0.01,0) [-81.92|81.91] "m/s" Vector__XXX
 SG_ CAN_TX_TRACK_RANGE_ACCEL : 33|10@0- (0.05,0) [-25.6|25.55] "m/s^2" Vector__XXX
 SG_ CAN_TX_TRACK_RANGE : 18|11@0+ (0.1,0) [0|204.7] "m" Vector__XXX
 SG_ CAN_TX_TRACK_ONCOMING : 0|1@0+ (1,0) [0|1] "" Vector__XXX
 SG_ CAN_TX_TRACK_MED_RANGE_MODE : 55|2@0+ (1,0) [0|3] "" Vector__XXX
 SG_ CAN_TX_TRACK_LAT_RATE : 7|6@0- (0.25,0) [-8|7.75] "" Vector__XXX
 SG_ CAN_TX_TRACK_GROUPING_CHANGED : 1|1@0+ (1,0) [0|1] "" Vector__XXX
 SG_ CAN_TX_TRACK_BRIDGE_OBJECT : 39|1@0+ (1,0) [0|1] "" Vector__XXX
 SG_ CAN_TX_TRACK_ANGLE : 12|10@0- (0.1,0) [-51.2|51.1] "" Vector__XXX

BO_ 1295 Target16: 8 Vector__XXX
 SG_ CAN_TX_TRACK_WIDTH : 37|4@0+ (0.5,0) [0|7.5] "" Vector__XXX
 SG_ CAN_TX_TRACK_STATUS : 15|3@0+ (1,0) [0|7] "" Vector__XXX
 SG_ CAN_TX_TRACK_ROLLING_COUNT : 38|1@0+ (1,0) [0|1] "" Vector__XXX
 SG_ CAN_TX_TRACK_RANGE_RATE : 53|14@0- (0.01,0) [-81.92|81.91] "m/s" Vector__XXX
 SG_ CAN_TX_TRACK_RANGE_ACCEL : 33|10@0- (0.05,0) [-25.6|25.55] "m/s^2" Vector__XXX
 SG_ CAN_TX_TRACK_RANGE : 18|11@0+ (0.1,0) [0|204.7] "m" Vector__XXX
 SG_ CAN_TX_TRACK_ONCOMING : 0|1@0+ (1,0) [0|1] "" Vector__XXX
 SG_ CAN_TX_TRACK_MED_RANGE_MODE : 55|2@0+ (1,0) [0|3] "" Vector__XXX
 SG_ CAN_TX_TRACK_LAT_RATE : 7|6@0- (0.25,0) [-8|7.75] "" Vector__XXX
 SG_ CAN_TX_TRACK_GROUPING_CHANGED : 1|1@0+ (1,0) [0|1] "" Vector__XXX
 SG_ CAN_TX_TRACK_BRIDGE_OBJECT : 39|1@0+ (1,0) [0|1] "" Vector__XXX
 SG_ CAN_TX_TRACK_ANGLE : 12|10@0- (0.1,0) [-51.2|51.1] "" Vector__XXX

BO_ 1294 Target15: 8 Vector__XXX
 SG_ CAN_TX_TRACK_WIDTH : 37|4@0+ (0.5,0) [0|7.5] "" Vector__XXX
 SG_ CAN_TX_TRACK_STATUS : 15|3@0+ (1,0) [0|7] "" Vector__XXX
 SG_ CAN_TX_TRACK_ROLLING_COUNT : 38|1@0+ (1,0) [0|1] "" Vector__XXX
 SG_ CAN_TX_TRACK_RANGE_RATE : 53|14@0- (0.01,0) [-81.92|81.91] "m/s" Vector__XXX
 SG_ CAN_TX_TRACK_RANGE_ACCEL : 33|10@0- (0.05,0) [-25.6|25.55] "m/s^2" Vector__XXX
 SG_ CAN_TX_TRACK_RANGE : 18|11@0+ (0.1,0) [0|204.7] "m" Vector__XXX
 SG_ CAN_TX_TRACK_ONCOMING : 0|1@0+ (1,0) [0|1] "" Vector__XXX
 SG_ CAN_TX_TRACK_MED_RANGE_MODE : 55|2@0+ (1,0) [0|3] "" Vector__XXX
 SG_ CAN_TX_TRACK_LAT_RATE : 7|6@0- (0.25,0) [-8|7.75] "" Vector__XXX
 SG_ CAN_TX_TRACK_GROUPING_CHANGED : 1|1@0+ (1,0) [0|1] "" Vector__XXX
 SG_ CAN_TX_TRACK_BRIDGE_OBJECT : 39|1@0+ (1,0) [0|1] "" Vector__XXX
 SG_ CAN_TX_TRACK_ANGLE : 12|10@0- (0.1,0) [-51.2|51.1] "" Vector__XXX

BO_ 1293 Target14: 8 Vector__XXX
 SG_ CAN_TX_TRACK_WIDTH : 37|4@0+ (0.5,0) [0|7.5] "" Vector__XXX
 SG_ CAN_TX_TRACK_STATUS : 15|3@0+ (1,0) [0|7] "" Vector__XXX
 SG_ CAN_TX_TRACK_ROLLING_COUNT : 38|1@0+ (1,0) [0|1] "" Vector__XXX
 SG_ CAN_TX_TRACK_RANGE_RATE : 53|14@0- (0.01,0) [-81.92|81.91] "m/s" Vector__XXX
 SG_ CAN_TX_TRACK_RANGE_ACCEL : 33|10@0- (0.05,0) [-25.6|25.55] "m/s^2" Vector__XXX
 SG_ CAN_TX_TRACK_RANGE : 18|11@0+ (0.1,0) [0|204.7] "m" Vector__XXX
 SG_ CAN_TX_TRACK_ONCOMING : 0|1@0+ (1,0) [0|1] "" Vector__XXX
 SG_ CAN_TX_TRACK_MED_RANGE_MODE : 55|2@0+ (1,0) [0|3] "" Vector__XXX
 SG_ CAN_TX_TRACK_LAT_RATE : 7|6@0- (0.25,0) [-8|7.75] "" Vector__XXX
 SG_ CAN_TX_TRACK_GROUPING_CHANGED : 1|1@0+ (1,0) [0|1] "" Vector__XXX
 SG_ CAN_TX_TRACK_BRIDGE_OBJECT : 39|1@0+ (1,0) [0|1] "" Vector__XXX
 SG_ CAN_TX_TRACK_ANGLE : 12|10@0- (0.1,0) [-51.2|51.1] "" Vector__XXX

BO_ 1292 Target13: 8 Vector__XXX
 SG_ CAN_TX_TRACK_WIDTH : 37|4@0+ (0.5,0) [0|7.5] "" Vector__XXX
 SG_ CAN_TX_TRACK_STATUS : 15|3@0+ (1,0) [0|7] "" Vector__XXX
 SG_ CAN_TX_TRACK_ROLLING_COUNT : 38|1@0+ (1,0) [0|1] "" Vector__XXX
 SG_ CAN_TX_TRACK_RANGE_RATE : 53|14@0- (0.01,0) [-81.92|81.91] "m/s" Vector__XXX
 SG_ CAN_TX_TRACK_RANGE_ACCEL : 33|10@0- (0.05,0) [-25.6|25.55] "m/s^2" Vector__XXX
 SG_ CAN_TX_TRACK_RANGE : 18|11@0+ (0.1,0) [0|204.7] "m" Vector__XXX
 SG_ CAN_TX_TRACK_ONCOMING : 0|1@0+ (1,0) [0|1] "" Vector__XXX
 SG_ CAN_TX_TRACK_MED_RANGE_MODE : 55|2@0+ (1,0) [0|3] "" Vector__XXX
 SG_ CAN_TX_TRACK_LAT_RATE : 7|6@0- (0.25,0) [-8|7.75] "" Vector__XXX
 SG_ CAN_TX_TRACK_GROUPING_CHANGED : 1|1@0+ (1,0) [0|1] "" Vector__XXX
 SG_ CAN_TX_TRACK_BRIDGE_OBJECT : 39|1@0+ (1,0) [0|1] "" Vector__XXX
 SG_ CAN_TX_TRACK_ANGLE : 12|10@0- (0.1,0) [-51.2|51.1] "" Vector__XXX

BO_ 1291 Target12: 8 Vector__XXX
 SG_ CAN_TX_TRACK_WIDTH : 37|4@0+ (0.5,0) [0|7.5] "" Vector__XXX
 SG_ CAN_TX_TRACK_STATUS : 15|3@0+ (1,0) [0|7] "" Vector__XXX
 SG_ CAN_TX_TRACK_ROLLING_COUNT : 38|1@0+ (1,0) [0|1] "" Vector__XXX
 SG_ CAN_TX_TRACK_RANGE_RATE : 53|14@0- (0.01,0) [-81.92|81.91] "m/s" Vector__XXX
 SG_ CAN_TX_TRACK_RANGE_ACCEL : 33|10@0- (0.05,0) [-25.6|25.55] "m/s^2" Vector__XXX
 SG_ CAN_TX_TRACK_RANGE : 18|11@0+ (0.1,0) [0|204.7] "m" Vector__XXX
 SG_ CAN_TX_TRACK_ONCOMING : 0|1@0+ (1,0) [0|1] "" Vector__XXX
 SG_ CAN_TX_TRACK_MED_RANGE_MODE : 55|2@0+ (1,0) [0|3] "" Vector__XXX
 SG_ CAN_TX_TRACK_LAT_RATE : 7|6@0- (0.25,0) [-8|7.75] "" Vector__XXX
 SG_ CAN_TX_TRACK_GROUPING_CHANGED : 1|1@0+ (1,0) [0|1] "" Vector__XXX
 SG_ CAN_TX_TRACK_BRIDGE_OBJECT : 39|1@0+ (1,0) [0|1] "" Vector__XXX
 SG_ CAN_TX_TRACK_ANGLE : 12|10@0- (0.1,0) [-51.2|51.1] "" Vector__XXX

BO_ 1290 Target11: 8 Vector__XXX
 SG_ CAN_TX_TRACK_WIDTH : 37|4@0+ (0.5,0) [0|7.5] "" Vector__XXX
 SG_ CAN_TX_TRACK_STATUS : 15|3@0+ (1,0) [0|7] "" Vector__XXX
 SG_ CAN_TX_TRACK_ROLLING_COUNT : 38|1@0+ (1,0) [0|1] "" Vector__XXX
 SG_ CAN_TX_TRACK_RANGE_RATE : 53|14@0- (0.01,0) [-81.92|81.91] "m/s" Vector__XXX
 SG_ CAN_TX_TRACK_RANGE_ACCEL : 33|10@0- (0.05,0) [-25.6|25.55] "m/s^2" Vector__XXX
 SG_ CAN_TX_TRACK_RANGE : 18|11@0+ (0.1,0) [0|204.7] "m" Vector__XXX
 SG_ CAN_TX_TRACK_ONCOMING : 0|1@0+ (1,0) [0|1] "" Vector__XXX
 SG_ CAN_TX_TRACK_MED_RANGE_MODE : 55|2@0+ (1,0) [0|3] "" Vector__XXX
 SG_ CAN_TX_TRACK_LAT_RATE : 7|6@0- (0.25,0) [-8|7.75] "" Vector__XXX
 SG_ CAN_TX_TRACK_GROUPING_CHANGED : 1|1@0+ (1,0) [0|1] "" Vector__XXX
 SG_ CAN_TX_TRACK_BRIDGE_OBJECT : 39|1@0+ (1,0) [0|1] "" Vector__XXX
 SG_ CAN_TX_TRACK_ANGLE : 12|10@0- (0.1,0) [-51.2|51.1] "" Vector__XXX

BO_ 1289 Target10: 8 Vector__XXX
 SG_ CAN_TX_TRACK_WIDTH : 37|4@0+ (0.5,0) [0|7.5] "" Vector__XXX
 SG_ CAN_TX_TRACK_STATUS : 15|3@0+ (1,0) [0|7] "" Vector__XXX
 SG_ CAN_TX_TRACK_ROLLING_COUNT : 38|1@0+ (1,0) [0|1] "" Vector__XXX
 SG_ CAN_TX_TRACK_RANGE_RATE : 53|14@0- (0.01,0) [-81.92|81.91] "m/s" Vector__XXX
 SG_ CAN_TX_TRACK_RANGE_ACCEL : 33|10@0- (0.05,0) [-25.6|25.55] "m/s^2" Vector__XXX
 SG_ CAN_TX_TRACK_RANGE : 18|11@0+ (0.1,0) [0|204.7] "m" Vector__XXX
 SG_ CAN_TX_TRACK_ONCOMING : 0|1@0+ (1,0) [0|1] "" Vector__XXX
 SG_ CAN_TX_TRACK_MED_RANGE_MODE : 55|2@0+ (1,0) [0|3] "" Vector__XXX
 SG_ CAN_TX_TRACK_LAT_RATE : 7|6@0- (0.25,0) [-8|7.75] "" Vector__XXX
 SG_ CAN_TX_TRACK_GROUPING_CHANGED : 1|1@0+ (1,0) [0|1] "" Vector__XXX
 SG_ CAN_TX_TRACK_BRIDGE_OBJECT : 39|1@0+ (1,0) [0|1] "" Vector__XXX
 SG_ CAN_TX_TRACK_ANGLE : 12|10@0- (0.1,0) [-51.2|51.1] "" Vector__XXX

BO_ 1288 Target9: 8 Vector__XXX
 SG_ CAN_TX_TRACK_WIDTH : 37|4@0+ (0.5,0) [0|7.5] "" Vector__XXX
 SG_ CAN_TX_TRACK_STATUS : 15|3@0+ (1,0) [0|7] "" Vector__XXX
 SG_ CAN_TX_TRACK_ROLLING_COUNT : 38|1@0+ (1,0) [0|1] "" Vector__XXX
 SG_ CAN_TX_TRACK_RANGE_RATE : 53|14@0- (0.01,0) [-81.92|81.91] "m/s" Vector__XXX
 SG_ CAN_TX_TRACK_RANGE_ACCEL : 33|10@0- (0.05,0) [-25.6|25.55] "m/s^2" Vector__XXX
 SG_ CAN_TX_TRACK_RANGE : 18|11@0+ (0.1,0) [0|204.7] "m" Vector__XXX
 SG_ CAN_TX_TRACK_ONCOMING : 0|1@0+ (1,0) [0|1] "" Vector__XXX
 SG_ CAN_TX_TRACK_MED_RANGE_MODE : 55|2@0+ (1,0) [0|3] "" Vector__XXX
 SG_ CAN_TX_TRACK_LAT_RATE : 7|6@0- (0.25,0) [-8|7.75] "" Vector__XXX
 SG_ CAN_TX_TRACK_GROUPING_CHANGED : 1|1@0+ (1,0) [0|1] "" Vector__XXX
 SG_ CAN_TX_TRACK_BRIDGE_OBJECT : 39|1@0+ (1,0) [0|1] "" Vector__XXX
 SG_ CAN_TX_TRACK_ANGLE : 12|10@0- (0.1,0) [-51.2|51.1] "" Vector__XXX

BO_ 1287 Target8: 8 Vector__XXX
 SG_ CAN_TX_TRACK_WIDTH : 37|4@0+ (0.5,0) [0|7.5] "" Vector__XXX
 SG_ CAN_TX_TRACK_STATUS : 15|3@0+ (1,0) [0|7] "" Vector__XXX
 SG_ CAN_TX_TRACK_ROLLING_COUNT : 38|1@0+ (1,0) [0|1] "" Vector__XXX
 SG_ CAN_TX_TRACK_RANGE_RATE : 53|14@0- (0.01,0) [-81.92|81.91] "m/s" Vector__XXX
 SG_ CAN_TX_TRACK_RANGE_ACCEL : 33|10@0- (0.05,0) [-25.6|25.55] "m/s^2" Vector__XXX
 SG_ CAN_TX_TRACK_RANGE : 18|11@0+ (0.1,0) [0|204.7] "m" Vector__XXX
 SG_ CAN_TX_TRACK_ONCOMING : 0|1@0+ (1,0) [0|1] "" Vector__XXX
 SG_ CAN_TX_TRACK_MED_RANGE_MODE : 55|2@0+ (1,0) [0|3] "" Vector__XXX
 SG_ CAN_TX_TRACK_LAT_RATE : 7|6@0- (0.25,0) [-8|7.75] "" Vector__XXX
 SG_ CAN_TX_TRACK_GROUPING_CHANGED : 1|1@0+ (1,0) [0|1] "" Vector__XXX
 SG_ CAN_TX_TRACK_BRIDGE_OBJECT : 39|1@0+ (1,0) [0|1] "" Vector__XXX
 SG_ CAN_TX_TRACK_ANGLE : 12|10@0- (0.1,0) [-51.2|51.1] "" Vector__XXX

BO_ 1285 Target6: 8 Vector__XXX
 SG_ CAN_TX_TRACK_WIDTH : 37|4@0+ (0.5,0) [0|7.5] "" Vector__XXX
 SG_ CAN_TX_TRACK_STATUS : 15|3@0+ (1,0) [0|7] "" Vector__XXX
 SG_ CAN_TX_TRACK_ROLLING_COUNT : 38|1@0+ (1,0) [0|1] "" Vector__XXX
 SG_ CAN_TX_TRACK_RANGE_RATE : 53|14@0- (0.01,0) [-81.92|81.91] "m/s" Vector__XXX
 SG_ CAN_TX_TRACK_RANGE_ACCEL : 33|10@0- (0.05,0) [-25.6|25.55] "m/s^2" Vector__XXX
 SG_ CAN_TX_TRACK_RANGE : 18|11@0+ (0.1,0) [0|204.7] "m" Vector__XXX
 SG_ CAN_TX_TRACK_ONCOMING : 0|1@0+ (1,0) [0|1] "" Vector__XXX
 SG_ CAN_TX_TRACK_MED_RANGE_MODE : 55|2@0+ (1,0) [0|3] "" Vector__XXX
 SG_ CAN_TX_TRACK_LAT_RATE : 7|6@0- (0.25,0) [-8|7.75] "" Vector__XXX
 SG_ CAN_TX_TRACK_GROUPING_CHANGED : 1|1@0+ (1,0) [0|1] "" Vector__XXX
 SG_ CAN_TX_TRACK_BRIDGE_OBJECT : 39|1@0+ (1,0) [0|1] "" Vector__XXX
 SG_ CAN_TX_TRACK_ANGLE : 12|10@0- (0.1,0) [-51.2|51.1] "" Vector__XXX

BO_ 1286 Target7: 8 Vector__XXX
 SG_ CAN_TX_TRACK_WIDTH : 37|4@0+ (0.5,0) [0|7.5] "" Vector__XXX
 SG_ CAN_TX_TRACK_STATUS : 15|3@0+ (1,0) [0|7] "" Vector__XXX
 SG_ CAN_TX_TRACK_ROLLING_COUNT : 38|1@0+ (1,0) [0|1] "" Vector__XXX
 SG_ CAN_TX_TRACK_RANGE_RATE : 53|14@0- (0.01,0) [-81.92|81.91] "m/s" Vector__XXX
 SG_ CAN_TX_TRACK_RANGE_ACCEL : 33|10@0- (0.05,0) [-25.6|25.55] "m/s^2" Vector__XXX
 SG_ CAN_TX_TRACK_RANGE : 18|11@0+ (0.1,0) [0|204.7] "m" Vector__XXX
 SG_ CAN_TX_TRACK_ONCOMING : 0|1@0+ (1,0) [0|1] "" Vector__XXX
 SG_ CAN_TX_TRACK_MED_RANGE_MODE : 55|2@0+ (1,0) [0|3] "" Vector__XXX
 SG_ CAN_TX_TRACK_LAT_RATE : 7|6@0- (0.25,0) [-8|7.75] "" Vector__XXX
 SG_ CAN_TX_TRACK_GROUPING_CHANGED : 1|1@0+ (1,0) [0|1] "" Vector__XXX
 SG_ CAN_TX_TRACK_BRIDGE_OBJECT : 39|1@0+ (1,0) [0|1] "" Vector__XXX
 SG_ CAN_TX_TRACK_ANGLE : 12|10@0- (0.1,0) [-51.2|51.1] "" Vector__XXX

BO_ 1284 Target5: 8 Vector__XXX
 SG_ CAN_TX_TRACK_WIDTH : 37|4@0+ (0.5,0) [0|7.5] "" Vector__XXX
 SG_ CAN_TX_TRACK_STATUS : 15|3@0+ (1,0) [0|7] "" Vector__XXX
 SG_ CAN_TX_TRACK_ROLLING_COUNT : 38|1@0+ (1,0) [0|1] "" Vector__XXX
 SG_ CAN_TX_TRACK_RANGE_RATE : 53|14@0- (0.01,0) [-81.92|81.91] "m/s" Vector__XXX
 SG_ CAN_TX_TRACK_RANGE_ACCEL : 33|10@0- (0.05,0) [-25.6|25.55] "m/s^2" Vector__XXX
 SG_ CAN_TX_TRACK_RANGE : 18|11@0+ (0.1,0) [0|204.7] "m" Vector__XXX
 SG_ CAN_TX_TRACK_ONCOMING : 0|1@0+ (1,0) [0|1] "" Vector__XXX
 SG_ CAN_TX_TRACK_MED_RANGE_MODE : 55|2@0+ (1,0) [0|3] "" Vector__XXX
 SG_ CAN_TX_TRACK_LAT_RATE : 7|6@0- (0.25,0) [-8|7.75] "" Vector__XXX
 SG_ CAN_TX_TRACK_GROUPING_CHANGED : 1|1@0+ (1,0) [0|1] "" Vector__XXX
 SG_ CAN_TX_TRACK_BRIDGE_OBJECT : 39|1@0+ (1,0) [0|1] "" Vector__XXX
 SG_ CAN_TX_TRACK_ANGLE : 12|10@0- (0.1,0) [-51.2|51.1] "" Vector__XXX

BO_ 1283 Target4: 8 Vector__XXX
 SG_ CAN_TX_TRACK_WIDTH : 37|4@0+ (0.5,0) [0|7.5] "" Vector__XXX
 SG_ CAN_TX_TRACK_STATUS : 15|3@0+ (1,0) [0|7] "" Vector__XXX
 SG_ CAN_TX_TRACK_ROLLING_COUNT : 38|1@0+ (1,0) [0|1] "" Vector__XXX
 SG_ CAN_TX_TRACK_RANGE_RATE : 53|14@0- (0.01,0) [-81.92|81.91] "m/s" Vector__XXX
 SG_ CAN_TX_TRACK_RANGE_ACCEL : 33|10@0- (0.05,0) [-25.6|25.55] "m/s^2" Vector__XXX
 SG_ CAN_TX_TRACK_RANGE : 18|11@0+ (0.1,0) [0|204.7] "m" Vector__XXX
 SG_ CAN_TX_TRACK_ONCOMING : 0|1@0+ (1,0) [0|1] "" Vector__XXX
 SG_ CAN_TX_TRACK_MED_RANGE_MODE : 55|2@0+ (1,0) [0|3] "" Vector__XXX
 SG_ CAN_TX_TRACK_LAT_RATE : 7|6@0- (0.25,0) [-8|7.75] "" Vector__XXX
 SG_ CAN_TX_TRACK_GROUPING_CHANGED : 1|1@0+ (1,0) [0|1] "" Vector__XXX
 SG_ CAN_TX_TRACK_BRIDGE_OBJECT : 39|1@0+ (1,0) [0|1] "" Vector__XXX
 SG_ CAN_TX_TRACK_ANGLE : 12|10@0- (0.1,0) [-51.2|51.1] "" Vector__XXX

BO_ 1282 Target3: 8 Vector__XXX
 SG_ CAN_TX_TRACK_WIDTH : 37|4@0+ (0.5,0) [0|7.5] "" Vector__XXX
 SG_ CAN_TX_TRACK_STATUS : 15|3@0+ (1,0) [0|7] "" Vector__XXX
 SG_ CAN_TX_TRACK_ROLLING_COUNT : 38|1@0+ (1,0) [0|1] "" Vector__XXX
 SG_ CAN_TX_TRACK_RANGE_RATE : 53|14@0- (0.01,0) [-81.92|81.91] "m/s" Vector__XXX
 SG_ CAN_TX_TRACK_RANGE_ACCEL : 33|10@0- (0.05,0) [-25.6|25.55] "m/s^2" Vector__XXX
 SG_ CAN_TX_TRACK_RANGE : 18|11@0+ (0.1,0) [0|204.7] "m" Vector__XXX
 SG_ CAN_TX_TRACK_ONCOMING : 0|1@0+ (1,0) [0|1] "" Vector__XXX
 SG_ CAN_TX_TRACK_MED_RANGE_MODE : 55|2@0+ (1,0) [0|3] "" Vector__XXX
 SG_ CAN_TX_TRACK_LAT_RATE : 7|6@0- (0.25,0) [-8|7.75] "" Vector__XXX
 SG_ CAN_TX_TRACK_GROUPING_CHANGED : 1|1@0+ (1,0) [0|1] "" Vector__XXX
 SG_ CAN_TX_TRACK_BRIDGE_OBJECT : 39|1@0+ (1,0) [0|1] "" Vector__XXX
 SG_ CAN_TX_TRACK_ANGLE : 12|10@0- (0.1,0) [-51.2|51.1] "" Vector__XXX

BO_ 1281 Target2: 8 Vector__XXX
 SG_ CAN_TX_TRACK_WIDTH : 37|4@0+ (0.5,0) [0|7.5] "" Vector__XXX
 SG_ CAN_TX_TRACK_STATUS : 15|3@0+ (1,0) [0|7] "" Vector__XXX
 SG_ CAN_TX_TRACK_ROLLING_COUNT : 38|1@0+ (1,0) [0|1] "" Vector__XXX
 SG_ CAN_TX_TRACK_RANGE_RATE : 53|14@0- (0.01,0) [-81.92|81.91] "m/s" Vector__XXX
 SG_ CAN_TX_TRACK_RANGE_ACCEL : 33|10@0- (0.05,0) [-25.6|25.55] "m/s^2" Vector__XXX
 SG_ CAN_TX_TRACK_RANGE : 18|11@0+ (0.1,0) [0|204.7] "m" Vector__XXX
 SG_ CAN_TX_TRACK_ONCOMING : 0|1@0+ (1,0) [0|1] "" Vector__XXX
 SG_ CAN_TX_TRACK_MED_RANGE_MODE : 55|2@0+ (1,0) [0|3] "" Vector__XXX
 SG_ CAN_TX_TRACK_LAT_RATE : 7|6@0- (0.25,0) [-8|7.75] "" Vector__XXX
 SG_ CAN_TX_TRACK_GROUPING_CHANGED : 1|1@0+ (1,0) [0|1] "" Vector__XXX
 SG_ CAN_TX_TRACK_BRIDGE_OBJECT : 39|1@0+ (1,0) [0|1] "" Vector__XXX
 SG_ CAN_TX_TRACK_ANGLE : 12|10@0- (0.1,0) [-51.2|51.1] "" Vector__XXX

BO_ 1524 VehicleData3: 8 Gateway
 SG_ CAN_RX_YAW_RATE_BIAS_SHIFT : 15|1@0+ (1,0) [0|1] "" Vector__XXX
 SG_ CAN_RX_WHEELBASE : 55|8@0+ (2,200) [200|710] "cm" Vector__XXX
 SG_ CAN_RX_STEERING_GEAR_RATIO : 63|8@0+ (0.125,0) [0|31.875] "" Vector__XXX
 SG_ CAN_RX_OVERSTEER_UNDERSTEER : 7|8@0- (1,0) [-128|127] "%" Vector__XXX
 SG_ CAN_RX_FUNNEL_OFFSET_RIGHT : 31|8@0- (0.1,0) [-12.8|12.7] "m" Vector__XXX
 SG_ CAN_RX_FUNNEL_OFFSET_LEFT : 23|8@0- (0.1,0) [-12.8|12.7] "m" Vector__XXX
 SG_ CAN_RX_DISTANCE_REAR_AXLE : 47|8@0+ (2,200) [200|710] "cm" Vector__XXX
 SG_ CAN_RX_CW_BLOCKAGE_TRESHOLD : 39|8@0+ (0.0078125,0) [0|1.9921875] "" Vector__XXX
 SG_ CAN_RX_BEAMWIDTH_VERT : 14|7@0+ (0.0625,0) [0|7.9375] "deg" Vector__XXX

BO_ 1523 FactoryAlignment: 8 Gateway

BO_ 1522 Vehicle_Data2: 8 Gateway
 SG_ CAN_RX_WHEEL_SLIP : 41|2@0+ (1,0) [0|3] "" Vector__XXX
 SG_ CAN_RX_SERV_ALIGN_UPDATES_NEED : 55|8@0+ (1,0) [0|255] "" Vector__XXX
 SG_ CAN_RX_SERV_ALIGN_TYPE : 47|1@0+ (1,0) [0|1] "" Vector__XXX
 SG_ CAN_RX_RADAR_HEIGHT : 38|7@0+ (1,0) [0|127] "cm" Vector__XXX
 SG_ CAN_RX_RADAR_FOV_MR : 30|7@0+ (1,0) [0|127] "deg" Vector__XXX
 SG_ CAN_RX_RADAR_FOV_LR : 19|5@0+ (1,0) [0|31] "deg" Vector__XXX
 SG_ CAN_RX_LONG_ACCEL_VALIDITY : 7|1@0+ (1,0) [0|1] "" Vector__XXX
 SG_ CAN_RX_LONG_ACCEL : 12|9@0- (0.03125,0) [-8|7.96875] "m/s^2" Vector__XXX
 SG_ CAN_RX_LAT_ACCEL_VALIDITY : 6|1@0+ (1,0) [0|1] "" Vector__XXX
 SG_ CAN_RX_LAT_ACCEL : 5|9@0- (0.03125,0) [-8|7.96875] "m/s^2" Vector__XXX
 SG_ CAN_RX_AUTO_ALIGN_DISABLE : 39|1@0+ (1,0) [0|1] "" Vector__XXX
 SG_ CAN_RX_AUTO_ALIGN_CONVERGED : 42|1@0+ (1,0) [0|1] "" Vector__XXX
 SG_ CAN_RX_ANGLE_MOUNTING_OFFSET : 63|8@0- (0.0625,0) [-8|7.9375] "deg" Vector__XXX
 SG_ CAN_RX_AALIGN_AVG_CTR_TOTAL : 45|3@0+ (250,250) [250|2000] "" Vector__XXX

BO_ 1512 CIPV_Targets_Etc: 8 ESR
 SG_ CAN_RX_CIPV_TARGETS_BYTE_0 : 0|8@0+ (1,0) [0|255] "" Vector__XXX

BO_ 1472 ESR_Sim1_5C0: 8 Gateway
 SG_ SimFunction : 0|3@0+ (1,0) [0|7] "" Vector__XXX
 SG_ SimStatus : 3|2@0+ (1,0) [0|3] "" Vector__XXX
 SG_ SimTrackId : 5|2@0+ (1,0) [0|3] "" Vector__XXX
 SG_ SimAngle : 8|8@0- (0.5,0) [-64|63.5] "deg" Vector__XXX
 SG_ SimLateralPosition : 16|8@0- (0.25,0) [-32|31.75] "m" Vector__XXX
 SG_ SimLateralRate : 24|8@0- (0.25,0) [-32|31.75] "m/s" Vector__XXX
 SG_ SimRange : 32|8@0+ (1,0) [0|255] "m" Vector__XXX
 SG_ SimRangeAcceleration : 40|8@0- (0.25,0) [-32|31.75] "m/s^2" Vector__XXX
 SG_ SimRangeRate : 48|8@0- (0.25,0) [-32|31.75] "m/s" Vector__XXX
 SG_ SimReserved : 56|8@0+ (1,0) [0|255] "" Vector__XXX

BO_ 1511 ESR_History_Fault: 8 ESR

BO_ 1510 ESR_Active_Fault: 8 ESR

BO_ 1508 AD_Data: 8 ESR

BO_ 1489 SensorValidation2: 8 ESR
 SG_ CAN_TX_VALID_MR_SN : 7|8@0+ (1,0) [0|255] "" Vector__XXX
 SG_ CAN_TX_VALID_MR_RANGE_RATE : 31|16@0- (0.0078125,0) [-256|255.9921875] "m/s" Vector__XXX
 SG_ CAN_TX_VALID_MR_RANGE : 15|16@0+ (0.0078125,0) [0|511.9921875] "m" Vector__XXX
 SG_ CAN_TX_VALID_MR_POWER : 63|8@0- (1,0) [-128|127] "db" Vector__XXX
 SG_ CAN_TX_VALID_MR_ANGLE : 40|16@1- (0.0625,0) [-2048|2047.9375] "deg" Vector__XXX

BO_ 1488 SensorValidation: 8 ESR
 SG_ CAN_TX_VALID_LR_SN : 7|8@0+ (1,0) [0|255] "" Vector__XXX
 SG_ CAN_TX_VALID_LR_RANGE_RATE : 31|16@0- (0.0078125,0) [-256|255.9921875] "m/s" Vector__XXX
 SG_ CAN_TX_VALID_LR_RANGE : 15|16@0+ (0.0078125,0) [0|511.9921875] "m" Vector__XXX
 SG_ CAN_TX_VALID_LR_POWER : 63|8@0- (1,0) [-128|127] "db" Vector__XXX
 SG_ CAN_TX_VALID_LR_ANGLE : 47|16@0- (0.0625,0) [-2048|2047.9375] "deg" Vector__XXX

BO_ 1344 Track_Sensor: 1 ESR
 SG_ CAN_TX_TRACK_ROLLING_COUNT_2 : 4|1@0+ (1,0) [0|1] "" Vector__XXX

BO_ 1280 Target1: 8 ESR
 SG_ CAN_TX_TRACK_WIDTH : 37|4@0+ (0.5,0) [0|7.5] "" Vector__XXX
 SG_ CAN_TX_TRACK_STATUS : 15|3@0+ (1,0) [0|7] "" Vector__XXX
 SG_ CAN_TX_TRACK_ROLLING_COUNT : 38|1@0+ (1,0) [0|1] "" Vector__XXX
 SG_ CAN_TX_TRACK_RANGE_RATE : 53|14@0- (0.01,0) [-81.92|81.91] "m/s" Vector__XXX
 SG_ CAN_TX_TRACK_RANGE_ACCEL : 33|10@0- (0.05,0) [-25.6|25.55] "m/s^2" Vector__XXX
 SG_ CAN_TX_TRACK_RANGE : 18|11@0+ (0.1,0) [0|204.7] "m" Vector__XXX
 SG_ CAN_TX_TRACK_ONCOMING : 0|1@0+ (1,0) [0|1] "" Vector__XXX
 SG_ CAN_TX_TRACK_MED_RANGE_MODE : 55|2@0+ (1,0) [0|3] "" Vector__XXX
 SG_ CAN_TX_TRACK_LAT_RATE : 7|6@0- (0.25,0) [-8|7.75] "" Vector__XXX
 SG_ CAN_TX_TRACK_GROUPING_CHANGED : 1|1@0+ (1,0) [0|1] "" Vector__XXX
 SG_ CAN_TX_TRACK_BRIDGE_OBJECT : 39|1@0+ (1,0) [0|1] "" Vector__XXX
 SG_ CAN_TX_TRACK_ANGLE : 12|10@0- (0.1,0) [-51.2|51.1] "" Vector__XXX

BO_ 1265 SensorInput: 8 Gateway
 SG_ CAN_RX_USE_ANGLE_MISALIGNMENT : 23|1@0+ (1,0) [0|0] "" Vector__XXX
 SG_ CAN_RX_SCAN_INDEX_ACK : 7|16@0+ (1,0) [0|65535] "" Vector__XXX
 SG_ CAN_RX_LATERAL_MOUNTING_OFFSET : 47|8@0- (0.01563,0) [-2.00064|1.98501] "m" Vector__XXX
 SG_ CAN_RX_WIPER_STATUS : 57|1@0+ (1,0) [0|1] "" Vector__XXX
 SG_ CAN_RX_VOLVO_SHORT_TRACK_ROC : 31|4@0- (500,0) [-4000|3500] "m" Vector__XXX
 SG_ CAN_RX_VEHICLE_SPEED_VALIDITY : 61|1@0+ (1,0) [0|1] "" Vector__XXX
 SG_ CAN_RX_TURN_SIGNAL_STATUS : 63|2@0+ (1,0) [0|3] "" Vector__XXX
 SG_ CAN_RX_RAW_DATA_ENABLE : 56|1@0+ (1,0) [0|1] "" Vector__XXX
 SG_ CAN_RX_RADAR_CMD_RADIATE : 55|1@0+ (1,0) [0|1] "" Vector__XXX
 SG_ CAN_RX_MR_ONLY_TRANSMIT : 25|1@0+ (1,0) [0|0] "" Vector__XXX
 SG_ CAN_RX_MMR_UPSIDE_DOWN : 60|1@0+ (1,0) [0|1] "" Vector__XXX
 SG_ CAN_RX_MAXIMUM_TRACKS : 53|6@0+ (1,0) [0|63] "" Vector__XXX
 SG_ CAN_RX_LR_ONLY_TRANSMIT : 24|1@0+ (1,0) [0|0] "" Vector__XXX
 SG_ CAN_RX_HIGH_YAW_ANGLE : 21|6@0- (1,0) [-32|31] "deg" Vector__XXX
 SG_ CAN_RX_GROUPING_MODE : 59|2@0+ (1,0) [0|3] "" Vector__XXX
 SG_ CAN_RX_CLEAR_FAULTS : 22|1@0- (1,0) [0|0] "" Vector__XXX
 SG_ CAN_RX_BLOCKAGE_DISABLE : 54|1@0+ (1,0) [0|1] "" Vector__XXX
 SG_ CAN_RX_ANGLE_MISALIGNMENT : 39|8@0- (0.0625,0) [-8|7.9375] "deg" Vector__XXX

BO_ 1264 Vehicle_Data: 8 Gateway
 SG_ CAN_RX_YAW_RATE_VALIDITY : 31|1@0+ (1,0) [0|0] "" Vector__XXX
 SG_ CAN_RX_YAW_RATE : 11|12@0- (0.0625,0) [-128|127.9375] "deg/s" Vector__XXX
 SG_ CAN_RX_VEHICLE_SPEED_DIRECTION : 12|1@0+ (1,0) [0|1] "" Vector__XXX
 SG_ CAN_RX_VEHICLE_SPEED : 7|11@0+ (0.0625,0) [0|127.9375] "m/s" Vector__XXX
 SG_ CAN_RX_RADIUS_CURVATURE : 29|14@0- (1,0) [-8192|8191] "m" Vector__XXX
 SG_ CAN_RX_STEERING_VALIDITY : 47|1@0+ (1,0) [0|1] "" Vector__XXX
 SG_ CAN_RX_STEERING_ANGLE_SIGN : 46|1@0+ (1,0) [0|1] "" Vector__XXX
 SG_ CAN_RX_STEERING_ANGLE_RATE_SIGN : 30|1@0+ (1,0) [0|1] "" Vector__XXX
 SG_ CAN_RX_STEERING_ANGLE_RATE : 50|11@0+ (1,0) [0|2047] "deg/s" Vector__XXX
 SG_ CAN_RX_STEERING_ANGLE : 45|11@0+ (1,0) [0|2047] "deg" Vector__XXX

BO_ 1251 ESR_Output_InPath: 8 ESR
 SG_ CAN_TX_PATH_ID_ACC_MOVE : 15|8@0+ (1,0) [0|255] "" Vector__XXX
 SG_ CAN_TX_TRUCK_TARGET_DET : 7|1@0+ (1,0) [0|1] "" Vector__XXX
 SG_ CAN_TX_SIDELOBE_BLOCKATE : 5|1@0+ (1,0) [0|1] "" Vector__XXX
 SG_ CAN_TX_ROLLING_COUNT_3 : 1|2@0+ (1,0) [0|3] "" Vector__XXX
 SG_ CAN_TX_PATH_ID_FCW_STAT : 47|8@0+ (1,0) [0|255] "" Vector__XXX
 SG_ CAN_TX_PATH_ID_FCW_MOVE : 39|8@0+ (1,0) [0|255] "" Vector__XXX
 SG_ CAN_TX_PATH_ID_CMBB_STAT : 31|8@0+ (1,0) [0|255] "" Vector__XXX
 SG_ CAN_TX_PATH_ID_CMBB_MOVE : 23|8@0+ (1,0) [0|255] "" Vector__XXX
 SG_ CAN_TX_PATH_ID_ACC_STAT : 63|8@0+ (1,0) [0|255] "" Vector__XXX
 SG_ CAN_TX_PARTIAL_BLOCKAGE : 4|1@0+ (1,0) [0|1] "" Vector__XXX
 SG_ CAN_TX_LR_ONLY_GRATING_LOBE_DET : 6|1@0+ (1,0) [0|1] "" Vector__XXX
 SG_ CAN_TX_LMR_LR_MODE : 3|2@0+ (1,0) [0|3] "" Vector__XXX
 SG_ CAN_TX_AUTO_ALIGN_ANGLE : 55|8@0- (0.0625,0) [-8|7.9375] "" Vector__XXX

BO_ 1250 ESR_SW: 8 ESR
 SG_ CAN_TX_SW_VERSION_PLD : 63|8@0+ (1,0) [0|255] "" Vector__XXX
 SG_ CAN_TX_SW_VERSION_HOST : 15|24@0+ (1,0) [0|16777215] "" Vector__XXX
 SG_ CAN_TX_SERIAL_NUM : 39|24@0+ (1,0) [0|16777215] "" Vector__XXX
 SG_ CAN_TX_INTERFACE_VERSION : 7|4@0+ (1,0) [0|15] "" Vector__XXX
 SG_ CAN_TX_HW_VERSION : 3|4@0+ (1,0) [0|15] "" Vector__XXX

BO_ 1249 ESR_Status2: 8 ESR
 SG_ CAN_TX_YAW_RATE_BIAS : 47|8@0- (0.125,0) [-16|15.875] "" Vector__XXX
 SG_ CAN_TX_XCVR_OPERATIONAL : 12|1@0+ (1,0) [0|1] "" Vector__XXX
 SG_ CAN_TX_VEH_SPD_COMP_FACTOR : 39|6@0- (0.00195,1) [0.9376|1.06045] "" Vector__XXX
 SG_ CAN_TX_TEMPERATURE : 31|8@0- (1,0) [-128|127] "degC" Vector__XXX
 SG_ CAN_TX_SW_VERSION_DSP : 55|16@0+ (1,0) [0|65535] "" Vector__XXX
 SG_ CAN_TX_STEERING_ANGLE_ACK : 10|11@0+ (1,0) [0|2047] "deg" Vector__XXX
 SG_ CAN_TX_ROLLING_COUNT_2 : 1|2@0+ (1,0) [0|3] "" Vector__XXX
 SG_ CAN_TX_RAW_DATA_MODE : 11|1@0+ (1,0) [0|1] "" Vector__XXX
 SG_ CAN_TX_RANGE_PERF_ERROR : 14|1@0+ (1,0) [0|1] "" Vector__XXX
 SG_ CAN_TX_OVERHEAT_ERROR : 15|1@0+ (1,0) [0|1] "" Vector__XXX
 SG_ CAN_TX_MAXIMUM_TRACKS_ACK : 7|6@0+ (1,1) [1|64] "" Vector__XXX
 SG_ CAN_TX_INTERNAL_ERROR : 13|1@0+ (1,0) [0|1] "" Vector__XXX
 SG_ CAN_TX_GROUPING_MODE : 33|2@0+ (1,0) [0|3] "" Vector__XXX

BO_ 1248 ESR_Status: 8 ESR
 SG_ CAN_TX_COMM_ERROR : 14|1@0+ (1,0) [0|0] "" Vector__XXX
 SG_ CAN_TX_RADIUS_CURVATURE_CALC : 13|14@0- (1,0) [-8192|8191] "" Vector__XXX
 SG_ CAN_TX_YAW_RATE_CALC : 47|12@0- (0.0625,0) [-128|127.9375] "deg/s" Vector__XXX
 SG_ CAN_TX_VEHICLE_SPEED_CALC : 50|11@0+ (0.0625,0) [0|127.9375] "m/s" Vector__XXX
 SG_ CAN_TX_DSP_TIMESTAMP : 5|7@0+ (2,0) [0|254] "ms" Vector__XXX
 SG_ CAN_TX_SCAN_INDEX : 31|16@0+ (1,0) [0|65535] "" Vector__XXX
 SG_ CAN_TX_ROLLING_COUNT_1 : 6|2@1+ (1,0) [0|3] "" Vector__XXX

BA_DEF_  "BusType" STRING ;
BA_DEF_DEF_  "BusType" "CAN";
VAL_ 1264 CAN_RX_YAW_RATE_VALIDITY 1 "Valid" 0 "Invalid" ;
VAL_ 1264 CAN_RX_VEHICLE_SPEED_DIRECTION 1 "Reverse" 0 "Forward" ;
VAL_ 1264 CAN_RX_STEERING_VALIDITY 1 "True" 0 "False" ;
VAL_ 1264 CAN_RX_STEERING_ANGLE_SIGN 1 "Right Clockwise" 0 "Left CounterClockwise" ;
VAL_ 1264 CAN_RX_STEERING_ANGLE_RATE_SIGN 1 "Right Clockwise" 0 "Left CounterClockwise" ;
